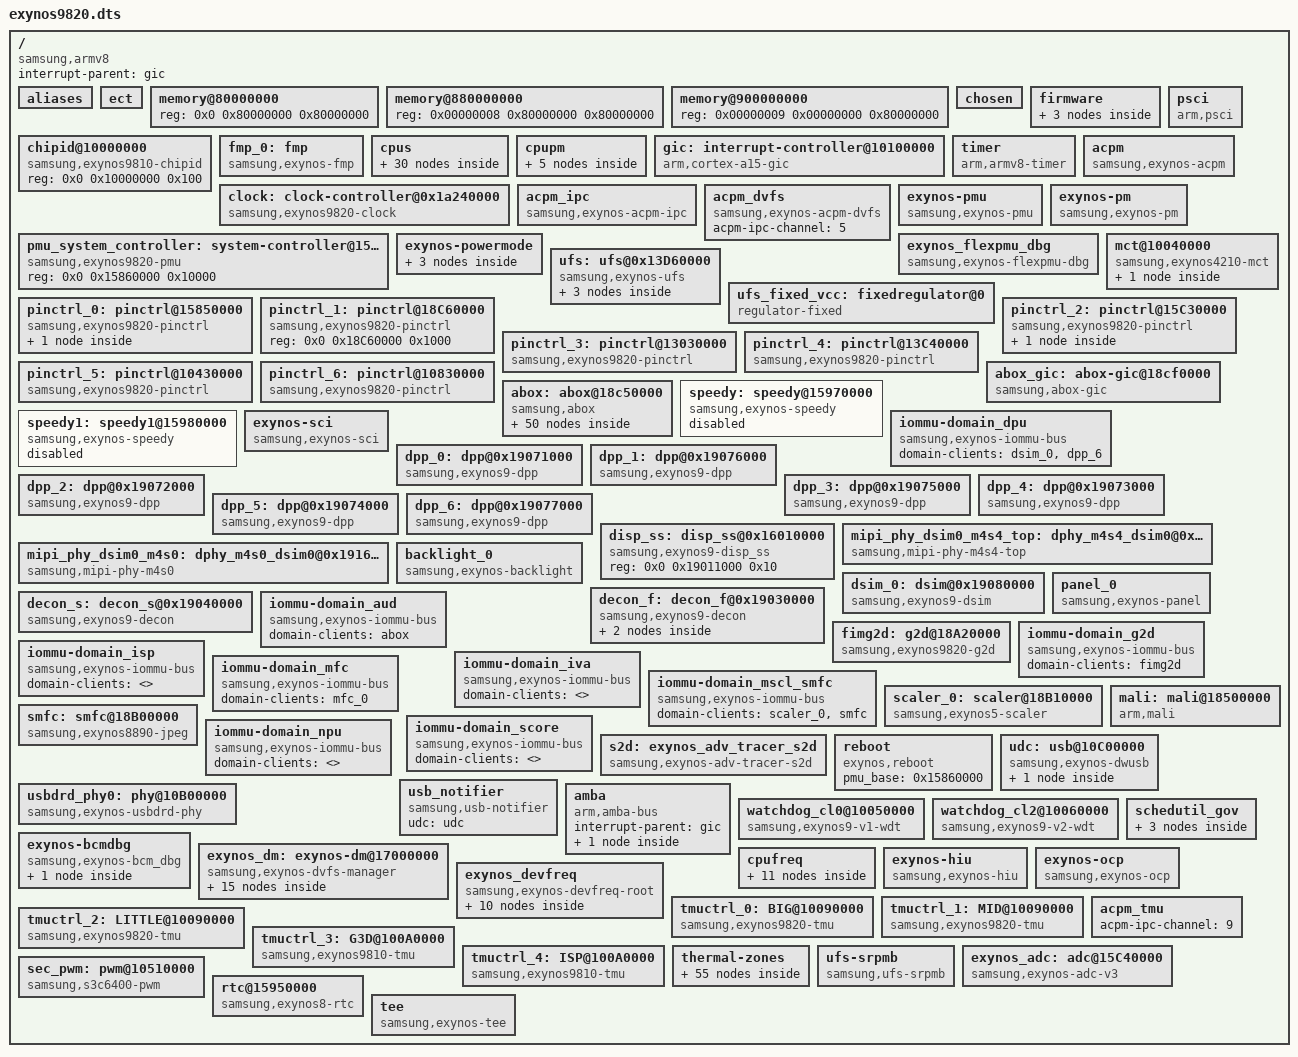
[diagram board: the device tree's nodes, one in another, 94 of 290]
/*
 * SAMSUNG EXYNOS9820 SoC device tree source
 *
 * Copyright (c) 2018 Samsung Electronics Co., Ltd.
 *		http://www.samsung.com
 *
 * SAMSUNG EXYNOS9820 SoC device nodes are listed in this file.
 * EXYNOS based board files can include this file and provide
 * values for board specfic bindings.
 *
 * This program is free software; you can redistribute it and/or modify
 * it under the terms of the GNU General Public License version 2 as
 * published by the Free Software Foundation.
 */

/dts-v1/;
#include <dt-bindings/interrupt-controller/arm-gic.h>
#include <dt-bindings/interrupt-controller/exynos9820.h>
#include <dt-bindings/soc/samsung/exynos-bcm_dbg.h>
#include "exynos9820-pm-domains.dtsi"
#include <dt-bindings/display/exynos-display.h>
#include "exynos9820-pinctrl.dtsi"
#include "exynos9820-rmem.dtsi"
#include <dt-bindings/clock/exynos9820.h>
#include "exynos9820-pmucal-dbg.dtsi"
#include "exynos9820-usi.dtsi"
#include "exynos9820-debug.dtsi"
#include <dt-bindings/ufs/ufs.h>
#include "exynos9820-sysmmu.dtsi"
#include <dt-bindings/soc/samsung/exynos9820-dm.h>
#include <dt-bindings/soc/samsung/exynos9820-devfreq.h>
#include <dt-bindings/thermal/thermal.h>
#include "exynos9820-mfc.dtsi"
#include "exynos9820-display-lcd.dtsi"

/ {
	compatible = "samsung,armv8", "samsung,exynos9820";
	interrupt-parent = <&gic>;
	#address-cells = <2>;
	#size-cells = <1>;

	aliases {
		pinctrl0 = &pinctrl_0;
		pinctrl1 = &pinctrl_1;
		pinctrl2 = &pinctrl_2;
		pinctrl3 = &pinctrl_3;
		pinctrl4 = &pinctrl_4;
		pinctrl5 = &pinctrl_5;
		pinctrl6 = &pinctrl_6;

		panel0 = &panel_0;
		dpp0 = &dpp_0;
		dpp1 = &dpp_1;
		dpp2 = &dpp_2;
		dpp3 = &dpp_3;
		dpp4 = &dpp_4;
		dpp5 = &dpp_5;
		dpp6 = &dpp_6;
		dsim0 = &dsim_0;
		bl0 = &backlight_0;
		fmp0 = &fmp_0;
		decon0 = &decon_f;
		decon1 = &decon_s;
		scaler0 = &scaler_0;
		mfc0 = &mfc_0;
	};

	ect {
		parameter_address = <0x90000000>;
		parameter_size = <0x3A000>;
	};

	memory@80000000 {
		device_type = "memory";
		reg = <0x0 0x80000000 0x80000000>;
	};

	memory@880000000 {
		device_type = "memory";
		reg = <0x00000008 0x80000000 0x80000000>;
	};

	memory@900000000 {
		device_type = "memory";
		reg = <0x00000009 0x00000000 0x80000000>;
	};

	chosen: chosen {
//		bootargs = "earlycon=exynos4210,0x10440000 console=ttySAC0,115200n8 root=/dev/ram0 rw ramdisk=8192 initrd=0x84000000,8M init=/linuxrc mem=512M clk_ignore_unused";
//		bootargs = "earlycon=exynos4210,0x10440000 console=ttySAC0,115200n8 skip_initramfs rootwait ro init=/init androidboot.dtbo_idx=0 bcm_setup=0xffffff80f8e00000 pmic_info=0x3 ccic_info=0x1 firmware_class.path=/vendor/firmware reserve-fimc=0xffffff80f9fe0000 sec_debug.cp=0 nohugeiomap epx_activate=true";
		bootargs = "console=ram skip_initramfs rootwait ro init=/init androidboot.dtbo_idx=0 bcm_setup=0xffffff80f8e00000 pmic_info=0x3 ccic_info=0x1 firmware_class.path=/vendor/firmware reserve-fimc=0xffffff80f9fe0000 sec_debug.cp=0 nohugeiomap epx_activate=true";
		linux,initrd-start = <0x84000000>;
		linux,initrd-end = <0x841FFFFF>;
	};

	firmware {
		android: android {
			compatible = "android,firmware";
			fstab {
				compatible = "android,fstab";
				vendor: vendor {
					compatible = "android,vendor";
					dev = "/dev/block/platform/13d60000.ufs/by-name/vendor";
					type = "ext4";
					mnt_flags = "ro";
					fsmgr_flags = "wait";
					status = "okay";
				};
			};
		};
	};

	chipid@10000000 {
		compatible = "samsung,exynos9810-chipid";
		reg = <0x0 0x10000000 0x100>;
	};

	fmp_0: fmp {
		compatible = "samsung,exynos-fmp";
	};

	cpus {
		#address-cells = <2>;
		#size-cells = <0>;

		cpu-map {
			cluster0 {
				coregroup0 {
					core0 {
						cpu = <&cpu0>;
					};
					core1 {
						cpu = <&cpu1>;
					};
					core2 {
						cpu = <&cpu2>;
					};
					core3 {
						cpu = <&cpu3>;
					};
				};
				coregroup1 {
					core0 {
						cpu = <&cpu4>;
					};
					core1 {
						cpu = <&cpu5>;
					};
				};
			};

			cluster1 {
				coregroup0 {
					core0 {
						cpu = <&cpu6>;
					};
					core1 {
						cpu = <&cpu7>;
					};
				};
			};

		};

		cpu0: cpu@0000 {
			device_type = "cpu";
			compatible = "arm,ananke", "arm,armv8";
			reg = <0x0 0x0000>;
			enable-method = "psci";
			cpu-idle-states = <&ANANKE_CPU_SLEEP>;
			sched-energy-data = <&ANANKE_ENERGY>;
		};

		cpu1: cpu@0001 {
			device_type = "cpu";
			compatible = "arm,ananke", "arm,armv8";
			reg = <0x0 0x0001>;
			enable-method = "psci";
			cpu-idle-states = <&ANANKE_CPU_SLEEP>;
			sched-energy-data = <&ANANKE_ENERGY>;
		};
		cpu2: cpu@0002 {
			device_type = "cpu";
			compatible = "arm,ananke", "arm,armv8";
			reg = <0x0 0x0002>;
			enable-method = "psci";
			cpu-idle-states = <&ANANKE_CPU_SLEEP>;
			sched-energy-data = <&ANANKE_ENERGY>;
		};
		cpu3: cpu@0003 {
			device_type = "cpu";
			compatible = "arm,ananke", "arm,armv8";
			reg = <0x0 0x0003>;
			enable-method = "psci";
			cpu-idle-states = <&ANANKE_CPU_SLEEP>;
			sched-energy-data = <&ANANKE_ENERGY>;
		};
		cpu4: cpu@0004 {
			device_type = "cpu";
			compatible = "arm,prometheus", "arm,armv8";
			reg = <0x0 0x0004>;
			enable-method = "psci";
			cpu-idle-states = <&PROMETHEUS_CPU_SLEEP>;
			sched-energy-data = <&PROMETHEUS_ENERGY>;
		};
		cpu5: cpu@0005 {
			device_type = "cpu";
			compatible = "arm,prometheus", "arm,armv8";
			reg = <0x0 0x0005>;
			enable-method = "psci";
			cpu-idle-states = <&PROMETHEUS_CPU_SLEEP>;
			sched-energy-data = <&PROMETHEUS_ENERGY>;
		};

		cpu6: cpu@0100 {
			device_type = "cpu";
			compatible = "arm,cheetah", "arm,armv8";
			reg = <0x0 0x0100>;
			enable-method = "psci";
			cpu-idle-states = <&CHEETAH_CPU_SLEEP>;
			sched-energy-data = <&CHEETAH_ENERGY>;
		};
		cpu7: cpu@0101 {
			device_type = "cpu";
			compatible = "arm,cheetah", "arm,armv8";
			reg = <0x0 0x0101>;
			enable-method = "psci";
			cpu-idle-states = <&CHEETAH_CPU_SLEEP>;
			sched-energy-data = <&CHEETAH_ENERGY>;
		};

		idle-states {
			entry-method = "arm,psci";

			ANANKE_CPU_SLEEP: ananke-cpu-sleep {
				idle-state-name = "c2";
				compatible = "exynos,idle-state";
				arm,psci-suspend-param = <0x0010000>;
				entry-latency-us = <70>;
				exit-latency-us = <160>;
				min-residency-us = <2000>;
				status = "okay";
			};

			PROMETHEUS_CPU_SLEEP: prometheus-cpu-sleep {
				idle-state-name = "c2";
				compatible = "exynos,idle-state";
				arm,psci-suspend-param = <0x0010000>;
				entry-latency-us = <150>;
				exit-latency-us = <190>;
				min-residency-us = <2500>;
				status = "okay";
			};

			CHEETAH_CPU_SLEEP: cheetah-cpu-sleep {
				idle-state-name = "c2";
				compatible = "exynos,idle-state";
				arm,psci-suspend-param = <0x0010000>;
				entry-latency-us = <235>;
				exit-latency-us = <220>;
				min-residency-us = <3500>;
				status = "okay";
			};
		};

		energy-data {
			ANANKE_ENERGY: ananke-energy {
				capacity-mips = <272>;
				power-coefficient = <160>;
				capacity-mips-s = <215>;
				power-coefficient-s = <130>;
			};
			PROMETHEUS_ENERGY: prometheus-energy {
				capacity-mips = <531>;
				power-coefficient = <320>;
				capacity-mips-s = <346>;
				power-coefficient-s = <259>;
			};
			CHEETAH_ENERGY: cheetah-energy {
				capacity-mips = <785>;
				power-coefficient = <760>;
				capacity-mips-s = <365>;
				power-coefficient-s = <506>;
			};
		};
	};

	psci {
		compatible = "arm,psci";
		method = "smc";
		cpu_suspend = <0xC4000001>;
		cpu_off = <0x84000002>;
		cpu_on = <0xC4000003>;
	};

	cpupm {
		#define POWERMODE_TYPE_CLUSTER	0
		#define POWERMODE_TYPE_SYSTEM	1

		cpd_cl0 {
			device_type = "cpupm";
			target-residency = <10000>;
			psci-index = <128>;
			type = <POWERMODE_TYPE_CLUSTER>;
			siblings = "0-5";
		};

		cpd_cl1 {
			device_type = "cpupm";
			target-residency = <10000>;
			psci-index = <128>;
			type = <POWERMODE_TYPE_CLUSTER>;
			siblings = "6-7";
			entry-allowed = "6-7";
		};

		vcpu_topology {
			vcluster_cnt = <3>;
			vcluster0_sibling = "0-3";
			vcluster1_sibling = "4-5";
			vcluster2_sibling = "6-7";
		};

		sicd {
			device_type = "cpupm";
			target-residency = <10000>;
			psci-index = <256>;
			type = <POWERMODE_TYPE_SYSTEM>;
			siblings = "0-7";
			entry-allowed = "0-5";
			system-idle;
		};

		idle-ip {
			idle-ip-list =
				"10510000.pwm",		/* [ 0] pwm      */
				"15c40000.adc",		/* [ 1] adc      */
				"10860000.hsi2c",	/* [ 2] hsi2c_0  */
				"10870000.hsi2c",	/* [ 3] hsi2c_1  */
				"10880000.hsi2c",	/* [ 4] hsi2c_2  */
				"10890000.hsi2c",	/* [ 5] hsi2c_3  */
				"10450000.hsi2c",	/* [ 6] hsi2c_4  */
				"10460000.hsi2c",	/* [ 7] hsi2c_5  */
				"10470000.hsi2c",	/* [ 8] hsi2c_6  */
				"10480000.hsi2c",	/* [ 9] hsi2c_7  */
				"10490000.hsi2c",	/* [10] hsi2c_8  */
				"104a0000.hsi2c",	/* [11] hsi2c_9  */
				"104b0000.hsi2c",	/* [12] hsi2c_10 */
				"104c0000.hsi2c",	/* [13] hsi2c_11 */
				"104d0000.hsi2c",	/* [14] hsi2c_12 */
				"104e0000.hsi2c",	/* [15] hsi2c_13 */
				"104f0000.hsi2c",	/* [16] hsi2c_14 */
				"10500000.hsi2c",	/* [17] hsi2c_15 */
				"108a0000.hsi2c",	/* [18] hsi2c_16 */
				"108b0000.hsi2c",	/* [19] hsi2c_17 */
				"108c0000.hsi2c",	/* [20] hsi2c_18 */
				"108d0000.hsi2c",	/* [21] hsi2c_19 */
				"108e0000.hsi2c",	/* [22] hsi2c_20 */
				"108f0000.hsi2c",	/* [23] hsi2c_21 */
				"10910000.hsi2c",	/* [25] hsi2c_23 */
				"10920000.hsi2c",	/* [26] hsi2c_24 */
				"10930000.hsi2c",	/* [27] hsi2c_25 */
				"10940000.hsi2c",	/* [28] hsi2c_26 */
				"10950000.hsi2c",	/* [29] hsi2c_27 */
				"10520000.hsi2c",	/* [30] hsi2c_28 */
				"10530000.hsi2c",	/* [31] hsi2c_29 */
				"10540000.hsi2c",	/* [32] hsi2c_30 */
				"10550000.hsi2c",	/* [33] hsi2c_31 */
				"10560000.hsi2c",	/* [34] hsi2c_32 */
				"10570000.hsi2c",	/* [35] hsi2c_33 */
				"10580000.hsi2c",	/* [36] hsi2c_34 */
				"10590000.hsi2c",	/* [37] hsi2c_35 */
				"10970000.hsi2c",	/* [38] hsi2c_36 */
				"10990000.hsi2c",	/* [39] hsi2c_37 */
				"109a0000.hsi2c",	/* [40] hsi2c_38 */
				"15d00000.hsi2c",	/* [41] hsi2c_39 */
				"15d10000.hsi2c",	/* [42] hsi2c_40 */
				"15d20000.hsi2c",	/* [43] hsi2c_41 */
				"15d30000.hsi2c",	/* [44] hsi2c_42 */
				"15d40000.hsi2c",	/* [45] hsi2c_43 */
				"15d50000.hsi2c",	/* [46] hsi2c_44 */
				"15d60000.hsi2c",	/* [47] hsi2c_45 */
				"15d70000.hsi2c",	/* [48] hsi2c_46 */
				"10850000.spi",		/* [49] spi_0    */
				"10450000.spi",		/* [50] spi_1    */
				"10470000.spi",		/* [51] spi_2    */
				"10490000.spi",		/* [52] spi_3    */
				"104b0000.spi",		/* [53] spi_4    */
				"104d0000.spi",		/* [54] spi_5    */
				"104f0000.spi",		/* [55] spi_6    */
				"108a0000.spi",		/* [56] spi_7    */
				"108c0000.spi",		/* [57] spi_8    */
				"108e0000.spi",		/* [58] spi_9    */
				"10900000.spi",		/* [59] spi_10   */
				"10920000.spi",		/* [60] spi_11   */
				"10940000.spi",		/* [61] spi_12   */
				"10520000.spi",		/* [62] spi_13   */
				"10540000.spi",		/* [63] spi_14   */
				"10560000.spi",		/* [64] spi_15   */
				"10580000.spi",		/* [65] spi_16   */
				"10970000.spi",		/* [66] spi_17   */
				"10990000.spi",		/* [67] spi_18   */
				"15d00000.spi",		/* [68] spi_19   */
				"15d20000.spi",		/* [69] spi_20   */
				"15d40000.spi",		/* [70] spi_21   */
				"15d60000.spi",		/* [71] spi_22   */
				"13d60000.ufs",		/* [72] ufs 	 */
				"10c00000.usb",		/* [73] usb 	 */
				"pd-aud",		/* [74] pd-aud	 */
				"pd-dcf",		/* [75] pd-dcf   */
				"pd-dcpost",		/* [76] pd-dcpost*/
				"pd-dcrd",		/* [77] pd-dcrd  */
				"pd-dpu",		/* [78] pd-dpu   */
				"pd-dspm",		/* [79] pd-dspm  */
				"pd-dsps",		/* [80] pd-dsps  */
				"pd-g2d",		/* [81] pd-g2d   */
				"pd-embedded_g3d",	/* [82] pd-embedded_g3d */
				"pd-isppre",		/* [83] pd-isppre*/
				"pd-isphq",		/* [84] pd-isphq */
				"pd-isplp",		/* [85] pd-isplp */
				"pd-iva",		/* [86] pd-iva   */
				"pd-mfc",		/* [87] pd-mfc   */
				"pd-vts",		/* [88] pd-vts   */
				"13ed0000.pcie0",	/* [89] pcie0    */
				"13120000.pcie1",	/* [90] pcie1    */
				"pd-vra2",		/* [91] vra2	 */
				"pd-npu0",		/* [92] npu0	 */
				"pd-npu1",		/* [93] npu1	 */
				"pd-fsys0a",		/* [94] fsys0a	 */
				"13d00000.dwmmc2",	/* [95] dwmmc2	 */
				"130b0000.displayport",	/* [96] displayport */
				"19080000.dsim";	/* [97] pd-dpu   */
				/* Append idle ip with ascending number from here
				 * Be advised that the end of entry must be with semicolon, not comma.
				 * and should be set in idle-ip-mask entry
				 */

				/* to here idle ip */

			fix-idle-ip =
				"acpm_dvfs",
				"dbg_core";
			fix-idle-ip-index =
				<110>,
				<111>;

			idle-ip-mask =
				<0>,  <1>,  <2>,  <3>,  <4>,  <5>,  <6>,  <7>,  <8>,  <9>,
				<10>, <11>, <12>, <13>, <14>, <15>, <16>, <17>, <18>, <19>,
				<20>, <21>, <22>, <23>, <24>, <25>, <26>, <27>, <28>, <29>,
				<30>, <31>, <32>, <33>, <34>, <35>, <36>, <37>, <38>, <39>,
				<40>, <41>, <42>, <43>, <44>, <45>, <46>, <47>, <48>, <49>,
				<50>, <51>, <52>, <53>, <54>, <55>, <56>, <57>, <58>, <59>,
				<60>, <61>, <62>, <63>, <64>, <65>, <66>, <67>, <68>, <69>,
				<70>, <71>, <72>, <73>,       <75>, <76>, <77>,       <79>,
				<80>, <81>, <82>, <83>, <84>, <85>, <86>, <87>,       <89>,
				<90>, <91>, <92>, <93>,       <95>, <96>, <97>,
				/* fix-idle-ip */
				<111>;
		};
	};

	gic:interrupt-controller@10100000 {
		compatible = "arm,cortex-a15-gic", "arm,cortex-a9-gic";
		#interrupt-cells = <3>;
		#address-cells = <0>;
		interrupt-controller;
		reg =	<0x0 0x10101000 0x1000>,
			<0x0 0x10102000 0x1000>,
			<0x0 0x10104000 0x2000>,
			<0x0 0x10106000 0x2000>;
		interrupts = <1 9 0xf04>;
	};

	timer {
	        compatible = "arm,armv8-timer";
		interrupts = <GIC_PPI 13
				(GIC_CPU_MASK_SIMPLE(8) | IRQ_TYPE_LEVEL_LOW)>,
			     <GIC_PPI 14
				(GIC_CPU_MASK_SIMPLE(8) | IRQ_TYPE_LEVEL_LOW)>,
			     <GIC_PPI 11
				(GIC_CPU_MASK_SIMPLE(8) | IRQ_TYPE_LEVEL_LOW)>,
			     <GIC_PPI 10
				(GIC_CPU_MASK_SIMPLE(8) | IRQ_TYPE_LEVEL_LOW)>;
	        clock-frequency = <26000000>;
		use-clocksource-only;
		use-physical-timer;
	};

	clock: clock-controller@0x1a240000 {
		compatible = "samsung,exynos9820-clock";
		reg = <0x0 0x1a240000 0x8000>;
		#clock-cells = <1>;
		acpm-ipc-channel = <0>;
	};

	acpm {
		compatible = "samsung,exynos-acpm";
		#address-cells = <2>;
		#size-cells = <1>;
		acpm-ipc-channel = <4>;
		fvmap_offset = <0xA400>;
		reg = <0x0 0x15830000 0x1000>;		/* TIMER_APM */
		reg-names = "timer_apm";
		peritimer-cnt = <0xFFFF>;
	};

	acpm_ipc {
		compatible = "samsung,exynos-acpm-ipc";
		#address-cells = <2>;
		#size-cells = <1>;
		interrupts = <GIC_SPI INTREQ__MAILBOX_APM2AP IRQ_TYPE_LEVEL_HIGH>;	/* AP2APM MAILBOX SPI NUM*/
		reg = <0x0 0x15900000 0x1000>,		/* AP2APM MAILBOX */
			<0x0 0x2039000 0x30000>;	/* APM SRAM */
		initdata-base = <0x7000>;
		num-timestamps = <32>;
		debug-log-level = <0>;
		logging-period = <500>;
		dump-base = <0x203C000>;
		dump-size = <0x2D000>;			/* 180KB */
	};

	acpm_dvfs {
		compatible = "samsung,exynos-acpm-dvfs";
		acpm-ipc-channel = <5>;
	};

	exynos-pmu {
		compatible = "samsung,exynos-pmu";
		samsung,syscon-phandle = <&pmu_system_controller>;
		reg = <0x0 0x15860000 0x10000>;
		reg-names = "pmu_alive";
	};

	pmu_system_controller: system-controller@15860000 {
		compatible = "samsung,exynos9820-pmu", "syscon";
		reg = <0x0 0x15860000 0x10000>;
	};

	exynos-pm {
		compatible = "samsung,exynos-pm";
		reg = <0x0 0x15850000 0x1000>,
		    <0x0 0x10101200 0x100>;
		reg-names = "gpio_alive_base",
			"gicd_ispendrn_base";
		num-eint = <34>;
		num-gic = <16>;
		suspend_mode_idx = <8>;		/* SYS_SLEEP */
		suspend_psci_idx = <1024>;	/* PSCI_SYSTEM_SLEEP */
		cp_call_mode_idx = <10>;	/* SYS_SLEEP_AUD_ON */
		cp_call_psci_idx = <1024>;	/* PSCI_SYSTEM_SLEEP */

		usbl2_suspend_available = <1>;	/* SYS_SLEEP_USBL2 */
		usbl2_suspend_mode_idx = <12>;	/* PSCI_SYSTEM_SLEEP */

			   /* WAKEUP_STAT,	WAKEUP2_STAT*/
		wakeup_stat = <0x3950>,		<0x3954>;
	};

	exynos-powermode {
		wakeup-masks {
			/*
			 * wakeup_mask configuration
			 *	        SICD		SICD_CPD	AFTR		STOP
			 *              LPD		LPA		ALPA		DSTOP
			 *              SLEEP		SLEEP_VTS_ON	SLEEP_AUD_ON	FAPO
			 *		USB_L2
			 */
			wakeup-mask {
				mask = <0x7ff81fff>,	<0x0>,		<0x0>,		<0x0>,
				       <0x0>,		<0x0>,		<0x0>,		<0x0>,
				       <0x1f6f>,	<0x1f6f>,	<0x1f6f>,	<0x0>,
				       <0x81f6f>;
				mask-offset = <0x3944>;
				stat-offset = <0x3950>;
			};
			wakeup-mask2 {
				mask = <0xf>,		<0x0>,		<0x0>,		<0x0>,
				       <0x0>,		<0x0>,		<0x0>,		<0x0>,
				       <0xf>,		<0xf>,		<0xf>,		<0x0>,
				       <0xc>;
				mask-offset = <0x3964>;
				stat-offset = <0x3954>;
			};
		};
	};

	exynos_flexpmu_dbg {
		compatible = "samsung,exynos-flexpmu-dbg";
		#address-cells = <2>;
		#size-cells = <1>;
		data-base = <0x204bc00>;
		data-size = <0x400>;
	};

	mct@10040000 {
		compatible = "samsung,exynos4210-mct";
		reg = <0x0 0x10040000 0x800>;
		interrupt-controller;
		#interrupt-cells = <1>;
		interrupt-parent = <&mct_map>;
		interrupts =	<0>, <1>, <2>, <3>,
				<4>, <5>, <6>, <7>,
				<8>, <9>, <10>, <11>;
		clocks = <&clock 1>, <&clock 15>;
		clock-names = "fin_pll", "mct";
		use-clockevent-only;

		mct_map: mct-map {
			#interrupt-cells = <1>;
			#address-cells = <0>;
			#size-cells = <0>;
			interrupt-map = <0 &gic 0 INTREQ__MCT_G0 IRQ_TYPE_LEVEL_HIGH>,
					<1 &gic 0 INTREQ__MCT_G1 IRQ_TYPE_LEVEL_HIGH>,
					<2 &gic 0 INTREQ__MCT_G2 IRQ_TYPE_LEVEL_HIGH>,
					<3 &gic 0 INTREQ__MCT_G3 IRQ_TYPE_LEVEL_HIGH>,
					<4 &gic 0 INTREQ__MCT_L0 IRQ_TYPE_LEVEL_HIGH>,
					<5 &gic 0 INTREQ__MCT_L1 IRQ_TYPE_LEVEL_HIGH>,
					<6 &gic 0 INTREQ__MCT_L2 IRQ_TYPE_LEVEL_HIGH>,
					<7 &gic 0 INTREQ__MCT_L3 IRQ_TYPE_LEVEL_HIGH>,
					<8 &gic 0 INTREQ__MCT_L4 IRQ_TYPE_LEVEL_HIGH>,
					<9 &gic 0 INTREQ__MCT_L5 IRQ_TYPE_LEVEL_HIGH>,
					<10 &gic 0 INTREQ__MCT_L6 IRQ_TYPE_LEVEL_HIGH>,
					<11 &gic 0 INTREQ__MCT_L7 IRQ_TYPE_LEVEL_HIGH>;
		};
	};

	ufs: ufs@0x13D60000 {
		/* ----------------------- */
		/* 1. SYSTEM CONFIGURATION */
		/* ----------------------- */
		compatible ="samsung,exynos-ufs";
		#address-cells = <2>;
		#size-cells = <1>;
		ranges;

		reg =
			<0x0 0x13D60000 0x200>,	/* 0: HCI standard */
			<0x0 0x13D61100 0x200>,	/* 1: Vendor specificed */
			<0x0 0x13D50000 0x8000>,	/* 2: UNIPRO */
			<0x0 0x13D70000 0x100>;	/* 3: UFS protector */
		interrupts = <GIC_SPI INTREQ__UFS_EMBD IRQ_TYPE_LEVEL_HIGH>;
		pinctrl-names = "default";
		pinctrl-0 = <&ufs_rst_n &ufs_refclk_out>;
		clocks =
			/* aclk clock */
			<&clock GATE_UFS_EMBD>,
			/* unipro clocks */
			<&clock UFS_EMBD>;

		clock-names =
			/* aclk clocks */
			"GATE_UFS_EMBD",
			/* unipro clocks */
			"UFS_EMBD";

		/* PM QoS for INT power domain */
		ufs-pm-qos-int = <400000>;

		/* PM QoS for FSYS0 power domain */


		/* DMA coherent callback, should be coupled with 'ufs-sys' */
		dma-coherent;

		/* ----------------------- */
		/* 2. UFS COMMON           */
		/* ----------------------- */
		freq-table-hz = <0 0>, <0 0>;

		vcc-supply = <&ufs_fixed_vcc>;
		vcc-fixed-regulator;


		/* ----------------------- */
		/* 3. UFS EXYNOS           */
		/* ----------------------- */
		hw-rev = <UFS_VER_0006>;

		/* power mode change */
		ufs,pmd-attr-lane = /bits/ 8 <2>;
		ufs,pmd-attr-gear = /bits/ 8 <3>;

		/* hiberantion */
		ufs-rx-min-activate-time-cap = <3>;
		ufs-rx-hibern8-time-cap = <2>;
		ufs-tx-hibern8-time-cap = <2>;

                /* evt version 1.x for UFS CAL */
		evt-ver = /bits/ 8 <1>;

		/* board type for UFS CAL */
		brd-for-cal = /bits/ 8 <1>;  /* (1:SMDK, 16:UNIV) board */
		fmp-id = <0>;
		smu-id = <0>;

		/* ----------------------- */
		/* 4. ADDITIONAL NODES     */
		/* ----------------------- */
		/* PHY isolation */
		ufs-phy {
			#address-cells = <2>;
			#size-cells = <1>;
			ranges;
			reg = <0x0 0x13D64000 0x800>;

		};

		/* SYSREG */
		ufs-io-coherency {
			#address-cells = <2>;
			#size-cells = <1>;
			ranges;

			reg =
				<0x0 0x13C10700 0x4>;

			mask = <(BIT_22 | BIT_23)>;
			bits = <(BIT_22 | BIT_23)>;
		};

		ufs-cport {
			reg =
			<0x0 0x13D68000 0x804>;
		};
	};

	ufs_fixed_vcc: fixedregulator@0 {
		       compatible = "regulator-fixed";
		       regulator-name = "ufs-vcc";
		       gpio = <&gpd0 2 0>;
		       regulator-boot-on;
		       enable-active-high;
	};

	/* ALIVE */
	pinctrl_0: pinctrl@15850000 {
		compatible = "samsung,exynos9820-pinctrl";
		reg = <0x0 0x15850000 0x1000>;
		interrupts = <GIC_SPI INTREQ__ALIVE_EINT0 IRQ_TYPE_LEVEL_HIGH>, <GIC_SPI INTREQ__ALIVE_EINT1 IRQ_TYPE_LEVEL_HIGH>, <GIC_SPI INTREQ__ALIVE_EINT2 IRQ_TYPE_LEVEL_HIGH>,
			     <GIC_SPI INTREQ__ALIVE_EINT3 IRQ_TYPE_LEVEL_HIGH>, <GIC_SPI INTREQ__ALIVE_EINT4 IRQ_TYPE_LEVEL_HIGH>, <GIC_SPI INTREQ__ALIVE_EINT5 IRQ_TYPE_LEVEL_HIGH>,
			     <GIC_SPI INTREQ__ALIVE_EINT6 IRQ_TYPE_LEVEL_HIGH>, <GIC_SPI INTREQ__ALIVE_EINT7 IRQ_TYPE_LEVEL_HIGH>, <GIC_SPI INTREQ__ALIVE_EINT8 IRQ_TYPE_LEVEL_HIGH>,
			     <GIC_SPI INTREQ__ALIVE_EINT9 IRQ_TYPE_LEVEL_HIGH>, <GIC_SPI INTREQ__ALIVE_EINT10 IRQ_TYPE_LEVEL_HIGH>, <GIC_SPI INTREQ__ALIVE_EINT11 IRQ_TYPE_LEVEL_HIGH>,
			     <GIC_SPI INTREQ__ALIVE_EINT12 IRQ_TYPE_LEVEL_HIGH>, <GIC_SPI INTREQ__ALIVE_EINT13 IRQ_TYPE_LEVEL_HIGH>, <GIC_SPI INTREQ__ALIVE_EINT14 IRQ_TYPE_LEVEL_HIGH>,
			     <GIC_SPI INTREQ__ALIVE_EINT15 IRQ_TYPE_LEVEL_HIGH>, <GIC_SPI INTREQ__ALIVE_EINT16 IRQ_TYPE_LEVEL_HIGH>, <GIC_SPI INTREQ__ALIVE_EINT17 IRQ_TYPE_LEVEL_HIGH>,
			     <GIC_SPI INTREQ__ALIVE_EINT18 IRQ_TYPE_LEVEL_HIGH>, <GIC_SPI INTREQ__ALIVE_EINT19 IRQ_TYPE_LEVEL_HIGH>, <GIC_SPI INTREQ__ALIVE_EINT20 IRQ_TYPE_LEVEL_HIGH>,
			     <GIC_SPI INTREQ__ALIVE_EINT21 IRQ_TYPE_LEVEL_HIGH>, <GIC_SPI INTREQ__ALIVE_EINT22 IRQ_TYPE_LEVEL_HIGH>, <GIC_SPI INTREQ__ALIVE_EINT23 IRQ_TYPE_LEVEL_HIGH>,
			     <GIC_SPI INTREQ__ALIVE_EINT24 IRQ_TYPE_LEVEL_HIGH>, <GIC_SPI INTREQ__ALIVE_EINT25 IRQ_TYPE_LEVEL_HIGH>, <GIC_SPI INTREQ__ALIVE_EINT26 IRQ_TYPE_LEVEL_HIGH>,
			     <GIC_SPI INTREQ__ALIVE_EINT27 IRQ_TYPE_LEVEL_HIGH>, <GIC_SPI INTREQ__ALIVE_EINT28 IRQ_TYPE_LEVEL_HIGH>, <GIC_SPI INTREQ__ALIVE_EINT29 IRQ_TYPE_LEVEL_HIGH>,
			     <GIC_SPI INTREQ__ALIVE_EINT30 IRQ_TYPE_LEVEL_HIGH>, <GIC_SPI INTREQ__ALIVE_EINT31 IRQ_TYPE_LEVEL_HIGH>, <GIC_SPI INTREQ__ALIVE_EINT32 IRQ_TYPE_LEVEL_HIGH>,
			     <GIC_SPI INTREQ__ALIVE_EINT33 IRQ_TYPE_LEVEL_HIGH>;

		wakeup-interrupt-controller {
			compatible = "samsung,exynos7-wakeup-eint";
		};
	};

	/* AUD */
	pinctrl_1: pinctrl@18C60000{
		compatible = "samsung,exynos9820-pinctrl";
		reg = <0x0 0x18C60000 0x1000>;
	};

	/* CMGP */
	pinctrl_2: pinctrl@15C30000{
		compatible = "samsung,exynos9820-pinctrl";
		reg = <0x0 0x15C30000 0x1000>;
		interrupts = <GIC_SPI INTREQ__EXT_INTM0_0 IRQ_TYPE_LEVEL_HIGH>, <GIC_SPI INTREQ__EXT_INTM0_1 IRQ_TYPE_LEVEL_HIGH>,
			     <GIC_SPI INTREQ__EXT_INTM0_2 IRQ_TYPE_LEVEL_HIGH>, <GIC_SPI INTREQ__EXT_INTM0_3 IRQ_TYPE_LEVEL_HIGH>,
			     <GIC_SPI INTREQ__EXT_INTM0_4 IRQ_TYPE_LEVEL_HIGH>, <GIC_SPI INTREQ__EXT_INTM0_5 IRQ_TYPE_LEVEL_HIGH>,
			     <GIC_SPI INTREQ__EXT_INTM0_6 IRQ_TYPE_LEVEL_HIGH>, <GIC_SPI INTREQ__EXT_INTM0_7 IRQ_TYPE_LEVEL_HIGH>,
			     <GIC_SPI INTREQ__EXT_INTM1_0 IRQ_TYPE_LEVEL_HIGH>, <GIC_SPI INTREQ__EXT_INTM1_1 IRQ_TYPE_LEVEL_HIGH>,
			     <GIC_SPI INTREQ__EXT_INTM1_2 IRQ_TYPE_LEVEL_HIGH>, <GIC_SPI INTREQ__EXT_INTM1_3 IRQ_TYPE_LEVEL_HIGH>,
			     <GIC_SPI INTREQ__EXT_INTM1_4 IRQ_TYPE_LEVEL_HIGH>, <GIC_SPI INTREQ__EXT_INTM1_5 IRQ_TYPE_LEVEL_HIGH>,
			     <GIC_SPI INTREQ__EXT_INTM1_6 IRQ_TYPE_LEVEL_HIGH>, <GIC_SPI INTREQ__EXT_INTM1_7 IRQ_TYPE_LEVEL_HIGH>,
			     <GIC_SPI INTREQ__EXT_INTM1_8 IRQ_TYPE_LEVEL_HIGH>, <GIC_SPI INTREQ__EXT_INTM1_9 IRQ_TYPE_LEVEL_HIGH>,
			     <GIC_SPI INTREQ__EXT_INTM2_0 IRQ_TYPE_LEVEL_HIGH>, <GIC_SPI INTREQ__EXT_INTM2_1 IRQ_TYPE_LEVEL_HIGH>,
			     <GIC_SPI INTREQ__EXT_INTM2_2 IRQ_TYPE_LEVEL_HIGH>, <GIC_SPI INTREQ__EXT_INTM2_3 IRQ_TYPE_LEVEL_HIGH>,
			     <GIC_SPI INTREQ__EXT_INTM2_4 IRQ_TYPE_LEVEL_HIGH>, <GIC_SPI INTREQ__EXT_INTM2_5 IRQ_TYPE_LEVEL_HIGH>,
			     <GIC_SPI INTREQ__EXT_INTM2_6 IRQ_TYPE_LEVEL_HIGH>, <GIC_SPI INTREQ__EXT_INTM2_7 IRQ_TYPE_LEVEL_HIGH>,
			     <GIC_SPI INTREQ__EXT_INTM2_8 IRQ_TYPE_LEVEL_HIGH>, <GIC_SPI INTREQ__EXT_INTM2_9 IRQ_TYPE_LEVEL_HIGH>,
			     <GIC_SPI INTREQ__EXT_INTM3_0 IRQ_TYPE_LEVEL_HIGH>, <GIC_SPI INTREQ__EXT_INTM3_1 IRQ_TYPE_LEVEL_HIGH>;

		wakeup-interrupt-controller {
			compatible = "samsung,exynos7-wakeup-eint";
		};
	};

	/* FSYS0 */
	pinctrl_3: pinctrl@13030000 {
		compatible = "samsung,exynos9820-pinctrl";
		reg = <0x0 0x13030000 0x1000>;
		interrupts = <GIC_SPI INTREQ__GPIO_FSYS0 IRQ_TYPE_LEVEL_HIGH>;
	};

	/* FSYS1 */
	pinctrl_4: pinctrl@13C40000 {
		compatible = "samsung,exynos9820-pinctrl";
		reg = <0x0 0x13C40000 0x1000>;
		interrupts = <GIC_SPI INTREQ__GPIO_FSYS1 IRQ_TYPE_LEVEL_HIGH>;
	};

	/* PERIC0 */
	pinctrl_5: pinctrl@10430000 {
		compatible = "samsung,exynos9820-pinctrl";
		reg = <0x0 0x10430000 0x1000>;
		interrupts = <GIC_SPI INTREQ__GPIO_PERIC0 IRQ_TYPE_LEVEL_HIGH>;
	};

	/* PERIC1 */
	pinctrl_6: pinctrl@10830000 {
		compatible = "samsung,exynos9820-pinctrl";
		reg = <0x0 0x10830000 0x1000>;
		interrupts = <GIC_SPI INTREQ__GPIO_PERIC1 IRQ_TYPE_LEVEL_HIGH>;
	};
#if 0
	/* VTS */
	pinctrl_7: pinctrl@15580000 {
		compatible = "samsung,exynos9820-pinctrl";
		reg = <0x0 0x15580000 0x1000>;
	};
#endif

	abox_gic: abox-gic@18cf0000 {
		compatible = "samsung,abox-gic";
		reg = <0x0 0x18cf1000 0x1000>, <0x0 0x18cf2000 0x1004>;
		reg-names = "gicd", "gicc";
		interrupts = <GIC_SPI INTREQ__AUD_ABOX_GIC400 IRQ_TYPE_LEVEL_HIGH>;
	};

	abox: abox@18c50000 {
		compatible = "samsung,abox";
		reg = <0x0 0x18c50000 0x10000>, <0x0 0x18c10000 0x10000>,
			<0x0 0x18d00000 0x59000>, <0x0 0x18ce0000 0x10000>;
		reg-names = "sfr", "sysreg", "sram", "timer";
		#address-cells = <2>;
		#size-cells = <1>;
		ranges;
		iommus = <&sysmmu_aud>;
		clocks = <&clock PLL_OUT_AUD0>, <&clock PLL_OUT_AUD1>, <&clock DOUT_CLK_AUD_AUDIF>,
			<&clock DOUT_CLK_AUD_DMIC>, <&clock DOUT_CLK_AUD_BUS>, <&clock DOUT_CLK_AUD_CNT>;
		clock-names = "pll", "pll1", "audif", "dmic", "bus", "cnt";
		#sound-dai-cells = <1>;
		samsung,quirks = "try to asrc off";
		samsung,ipc-tx-offset = <0x2f000>;
		samsung,ipc-rx-offset = <0x2f300>;
		samsung,ipc-tx-ack-offset = <0x2f2fc>;
		samsung,ipc-rx-ack-offset = <0x2f5fc>;
		samsung,ipc-tx-area = <0x1 0x850000 0x4000>;
		samsung,ipc-rx-area = <0x1 0x854000 0x4000>;
		samsung,handshake-area = <0x0 0x2f2e0 0x20>;
		samsung,abox-gic = <&abox_gic>;
		samsung,uaif-max-div = <512>;
		samsung,pm-qos-int = <0 0 0 0 0>;
		samsung,pm-qos-aud = <1180000 800000 590000 394000 0>;

		abox_core0: abox-core@18c55000 {
			compatible = "samsung,abox-core";
			reg = <0x0 0x18c55000 0x80>;
			reg-names = "gpr";
			samsung,id = <0>;
			samsung,type = "CA32";
			samsung,pmu_power = <0x2d80 0x1>;
			samsung,pmu_enable = <0x2da0 0x1>;
			samsung,pmu_standby = <0x2da4 0x11>;
			abox_firmware_sram0: abox-firmware-sram0 {
				samsung,name = "calliope_sram.bin";
				samsung,area = <0>; /* 0:SRAM, 1:DRAM */
				samsung,offset = <0x0>;
			};
			abox_firmware_dram0: abox-firmware-dram0 {
				samsung,name = "calliope_dram.bin";
				samsung,area = <1>; /* 0:SRAM, 1:DRAM */
				samsung,offset = <0x0>;
			};
		};

		abox_core1: abox-core@18c55080 {
			compatible = "samsung,abox-core";
			reg = <0x0 0x18c55080 0x80>, <0x0 0x18c55100 0x4>;
			reg-names = "gpr", "status";
			samsung,id = <1>;
			samsung,type = "CA32";
			samsung,pmu_power = <0x2e00 0x1>;
			samsung,pmu_enable = <0x2e20 0x1>;
			samsung,pmu_standby = <0x2e24 0x1>;
			abox_firmware_sram1: abox-firmware-sram1 {
				samsung,name = "calliope_sram_2.bin";
				samsung,area = <0>; /* 0:SRAM, 1:DRAM */
				samsung,offset = <0x32000>;
			};
			abox_firmware_dram1: abox-firmware-dram1 {
				samsung,name = "calliope_dram_2.bin";
				samsung,area = <1>; /* 0:SRAM, 1:DRAM */
				samsung,offset = <0x280000>;
			};
		};

		abox_rdma_0: abox-rdma@18c51000 {
			compatible = "samsung,abox-rdma";
			reg = <0x0 0x18c51000 0x100>;
			reg-names = "sfr";
			samsung,id = <0>;
			samsung,type = "normal";
			samsung,buffer_type = "dma";
			#sound-dai-cells = <0>;
		};

		abox_rdma_1: abox-rdma@18c51100 {
			compatible = "samsung,abox-rdma";
			reg = <0x0 0x18c51100 0x100>;
			reg-names = "sfr";
			samsung,id = <1>;
			samsung,type = "normal";
			samsung,buffer_type = "dma";
			#sound-dai-cells = <0>;
		};

		abox_rdma_2: abox-rdma@18c51200 {
			compatible = "samsung,abox-rdma";
			reg = <0x0 0x18c51200 0x100>;
			reg-names = "sfr";
			samsung,id = <2>;
			samsung,type = "normal";
			samsung,buffer_type = "ion";
			#sound-dai-cells = <0>;
		};

		abox_rdma_3: abox-rdma@18c51300 {
			compatible = "samsung,abox-rdma";
			reg = <0x0 0x18c51300 0x100>;
			reg-names = "sfr";
			samsung,id = <3>;
			samsung,type = "sync";
			samsung,buffer_type = "dma";
			#sound-dai-cells = <0>;
		};

		abox_rdma_4: abox-rdma@18c51400 {
			compatible = "samsung,abox-rdma";
			reg = <0x0 0x18c51400 0x100>;
			reg-names = "sfr";
			samsung,id = <4>;
			samsung,type = "call";
			#sound-dai-cells = <0>;
			samsung,buffer_type = "dma";
			samsung,asrc-id = <10>;
		};

		abox_rdma_5: abox-rdma@18c51500 {
			compatible = "samsung,abox-rdma";
			reg = <0x0 0x18c51500 0x100>, <0x0 0x18d2f600 0x70>;
			reg-names = "sfr", "mailbox";
			samsung,id = <5>;
			samsung,type = "compress";
			samsung,buffer_type = "dma";
			#sound-dai-cells = <0>;
		};

		abox_rdma_6: abox-rdma@18c51600 {
			compatible = "samsung,abox-rdma";
			reg = <0x0 0x18c51600 0x100>;
			reg-names = "sfr";
			samsung,id = <6>;
			samsung,type = "realtime";
			samsung,buffer_type = "dma";
			#sound-dai-cells = <0>;
		};

		abox_rdma_7: abox-rdma@18c51700 {
			compatible = "samsung,abox-rdma";
			reg = <0x0 0x18c51700 0x100>;
			reg-names = "sfr";
			samsung,id = <7>;
			samsung,type = "realtime";
			samsung,buffer_type = "dma";
			#sound-dai-cells = <0>;
		};

		abox_rdma_8: abox-rdma@18c51800 {
			compatible = "samsung,abox-rdma";
			reg = <0x0 0x18c51800 0x100>;
			reg-names = "sfr";
			samsung,id = <8>;
			samsung,type = "normal";
			samsung,buffer_type = "dma";
			#sound-dai-cells = <0>;
		};

		abox_rdma_9: abox-rdma@18c51900 {
			compatible = "samsung,abox-rdma";
			reg = <0x0 0x18c51900 0x100>;
			reg-names = "sfr";
			samsung,id = <9>;
			samsung,type = "normal";
			samsung,buffer_type = "dma";
			#sound-dai-cells = <0>;
		};

		abox_rdma_10: abox-rdma@18c51a00 {
			compatible = "samsung,abox-rdma";
			reg = <0x0 0x18c51a00 0x100>;
			reg-names = "sfr";
			samsung,id = <10>;
			samsung,type = "normal";
			samsung,buffer_type = "dma";
			#sound-dai-cells = <0>;
		};

		abox_rdma_11: abox-rdma@18c51b00 {
			compatible = "samsung,abox-rdma";
			reg = <0x0 0x18c51b00 0x100>;
			reg-names = "sfr";
			samsung,id = <11>;
			samsung,type = "normal";
			samsung,buffer_type = "dma";
			#sound-dai-cells = <0>;
		};

		abox_wdma_0: abox-wdma@18c53000 {
			compatible = "samsung,abox-wdma";
			reg = <0x0 0x18c53000 0x100>;
			reg-names = "sfr";
			samsung,id = <0>;
			samsung,type = "realtime";
			samsung,buffer_type = "dma";
			#sound-dai-cells = <0>;
		};

		abox_wdma_1: abox-wdma@18c53100 {
			compatible = "samsung,abox-wdma";
			reg = <0x0 0x18c53100 0x100>;
			reg-names = "sfr";
			samsung,id = <1>;
			samsung,type = "normal";
			samsung,buffer_type = "ion";
			#sound-dai-cells = <0>;
		};

		abox_wdma_2: abox-wdma@18c53200 {
			compatible = "samsung,abox-wdma";
			reg = <0x0 0x18c53200 0x100>;
			reg-names = "sfr";
			samsung,id = <2>;
			samsung,type = "call";
			samsung,buffer_type = "dma";
			#sound-dai-cells = <0>;
			samsung,asrc-id = <6>;
		};

		abox_wdma_3: abox-wdma@18c53300 {
			compatible = "samsung,abox-wdma";
			reg = <0x0 0x18c53300 0x100>;
			reg-names = "sfr";
			samsung,id = <3>;
			samsung,type = "realtime";
			samsung,buffer_type = "dma";
			#sound-dai-cells = <0>;
		};

		abox_wdma_4: abox-wdma@18c53400 {
			compatible = "samsung,abox-wdma";
			reg = <0x0 0x18c53400 0x100>;
			reg-names = "sfr";
			samsung,id = <4>;
			samsung,type = "vi-sensing";
			samsung,buffer_type = "dma";
			#sound-dai-cells = <0>;
		};

		abox_wdma_5: abox-wdma@18c53500 {
			compatible = "samsung,abox-wdma";
			reg = <0x0 0x18c53500 0x100>;
			reg-names = "sfr";
			samsung,id = <5>;
			samsung,type = "normal";
			samsung,buffer_type = "dma";
			#sound-dai-cells = <0>;
		};

		abox_wdma_6: abox-wdma@18c53600 {
			compatible = "samsung,abox-wdma";
			reg = <0x0 0x18c53600 0x100>;
			reg-names = "sfr";
			samsung,id = <6>;
			samsung,type = "normal";
			samsung,buffer_type = "dma";
			#sound-dai-cells = <0>;
		};

		abox_wdma_7: abox-wdma@18c53700 {
			compatible = "samsung,abox-wdma";
			reg = <0x0 0x18c53700 0x100>;
			reg-names = "sfr";
			samsung,id = <7>;
			samsung,type = "normal";
			samsung,buffer_type = "dma";
			#sound-dai-cells = <0>;
		};

		abox_uaif_0: abox-uaif@18c50500 {
			compatible = "samsung,abox-uaif";
			reg = <0x0 0x18c50500 0x10>;
			reg-names = "sfr";
			id = <0>;
			clocks = <&clock DOUT_CLK_AUD_UAIF0>, <&clock GATE_ABOX_BCLK0>;
			clock-names = "bclk", "bclk_gate";
			pinctrl-names = "default", "sleep";
			pinctrl-0 = <&aud_i2s0_bus>;
			pinctrl-1 = <&aud_i2s0_idle>;
			#sound-dai-cells = <0>;
		};

		abox_uaif_1: abox-uaif@18c50510 {
			compatible = "samsung,abox-uaif";
			reg = <0x0 0x18c50510 0x10>;
			reg-names = "sfr";
			id = <1>;
			clocks = <&clock DOUT_CLK_AUD_UAIF1>, <&clock GATE_ABOX_BCLK1>;
			clock-names = "bclk", "bclk_gate";
			pinctrl-names = "default", "sleep";
			pinctrl-0 = <&aud_i2s1_bus>;
			pinctrl-1 = <&aud_i2s1_idle>;
			#sound-dai-cells = <0>;
		};

		abox_uaif_2: abox-uaif@18c50520 {
			compatible = "samsung,abox-uaif";
			reg = <0x0 0x18c50520 0x10>;
			reg-names = "sfr";
			id = <2>;
			clocks = <&clock DOUT_CLK_AUD_UAIF2>, <&clock GATE_ABOX_BCLK2>;
			clock-names = "bclk", "bclk_gate";
			pinctrl-names = "default", "sleep";
			pinctrl-0 = <&aud_i2s2_bus>;
			pinctrl-1 = <&aud_i2s2_idle>;
			#sound-dai-cells = <0>;
		};

		abox_uaif_3: abox-uaif@18c50530 {
			compatible = "samsung,abox-uaif";
			reg = <0x0 0x18c50530 0x10>;
			reg-names = "sfr";
			id = <3>;
			clocks = <&clock DOUT_CLK_AUD_UAIF3>, <&clock GATE_ABOX_BCLK3>;
			clock-names = "bclk", "bclk_gate";
			pinctrl-names = "default", "sleep";
			pinctrl-0 = <&aud_i2s3_bus>;
			pinctrl-1 = <&aud_i2s3_idle>;
			#sound-dai-cells = <0>;
		};

		abox_dsif: abox-dsif@18c50550 {
			compatible = "samsung,abox-dsif";
			reg = <0x0 0x18c50550 0x10>;
			reg-names = "sfr";
			id = <5>;
			clocks = <&clock DOUT_CLK_AUD_DSIF>, <&clock GATE_ABOX_BCLK_DSIF>;
			clock-names = "bclk", "bclk_gate";
			/* DSIF and UAIF2 shares GPIO
			 * pinctrl-names = "default", "sleep";
			 * pinctrl-0 = <&aud_dsd_bus>;
			 * pinctrl-1 = <&aud_dsd_idle>;
			 */
			#sound-dai-cells = <0>;
		};

		abox_effect: abox-effect@18d2e000 {
			compatible = "samsung,abox-effect";
			reg = <0x0 0x18d2e000 0x1000>;
			reg-names = "reg";
		};

		abox_debug: abox-debug@0 {
			compatible = "samsung,abox-debug";
			memory-region = <&abox_rmem>;
			reg = <0x0 0x0 0x0>;
		};

		abox_vss: abox-vss@0 {
			compatible = "samsung,abox-vss";
			samsung,magic-offset = <0x700000>;
			reg = <0x0 0x0 0x0>;
		};

		ext_bin_0: ext-bin@0 {
			status = "disabled";
			samsung,name = "dummy.bin";
			samsung,area = <1>; /* 0:SRAM, 1:DRAM, 2:VSS */
			samsung,offset = <0x0>;
		};
		ext_bin_1: ext-bin@1 {
			status = "disabled";
			samsung,name = "AP_AUDIO_SLSI.bin";
			samsung,area = <1>;
			samsung,offset = <0x7f0000>;
		};
		ext_bin_2: ext-bin@2 {
			status = "disabled";
			samsung,name = "APBargeIn_AUDIO_SLSI.bin";
			samsung,area = <1>;
			samsung,offset = <0x7ec000>;
		};
		ext_bin_3: ext-bin@3 {
			status = "okay";
			samsung,name = "SoundBoosterParam.bin";
			samsung,area = <1>;
			samsung,offset = <0x4fc000>;
		};
		ext_bin_4: ext-bin@4 {
			status = "okay";
			samsung,name = "APDV_AUDIO_SLSI.bin";
			samsung,area = <1>;
			samsung,offset = <0x4d0000>;
		};
		ext_bin_5: ext-bin@5 {
			status = "disabled";
			samsung,name = "APBiBF_AUDIO_SLSI.bin";
			samsung,area = <1>;
			samsung,offset = <0x7ef000>;
		};
		ext_bin_6: ext-bin@6 {
			status = "okay";
			samsung,name = "dnn.bin";
			samsung,area = <1>;
			samsung,offset = <0x500800>;
		};
		ext_bin_7: ext-bin@7 {
			status = "okay";
			samsung,name = "usbout.bin";
			samsung,area = <1>;
			samsung,offset = <0x1100000>;
		};
		ext_bin_8: ext-bin@8 {
			status = "okay";
			samsung,name = "usbin.bin";
			samsung,area = <1>;
			samsung,offset = <0x1110000>;
		};
		ext_bin_9: ext-bin@9 {
			status = "okay";
			samsung,name = "fmsb.bin";
			samsung,area = <1>;
			samsung,offset = <0x1120000>;
		};
		ext_bin_10: ext-bin@a {
			status = "okay";
			samsung,name = "txse1.bin";
			samsung,area = <1>;
			samsung,offset = <0x1200000>;
		};
		ext_bin_11: ext-bin@b {
			status = "okay";
			samsung,name = "rxse.bin";
			samsung,area = <1>;
			samsung,offset = <0x1300000>;
		};
		ext_bin_12: ext-bin@c {
			status = "okay";
			samsung,name = "txse2.bin";
			samsung,area = <1>;
			samsung,offset = <0x13b0000>;
		};
		ext_bin_13: ext-bin@d {
			status = "okay";
			samsung,name = "a2dpcom.bin";
			samsung,area = <1>;
			samsung,offset = <0x13e2000>;
		};
		ext_bin_14: ext-bin@e {
			status = "disabled";
			samsung,name = "bidirmic.bin";
			samsung,area = <1>;
			samsung,offset = <0x1414000>;
		};
		ext_bin_15: ext-bin@f {
			status = "okay";
			samsung,name = "calliope2.dt";
			samsung,area = <1>;
			samsung,offset = <0x11fe000>;
			samsung,mixer-control;
		};
	};

	speedy: speedy@15970000 {
		compatible = "samsung,exynos-speedy";
		reg = <0x0 0x15970000 0x2000>;
		interrupts = <GIC_SPI INTREQ__SPEEDY_APM IRQ_TYPE_LEVEL_HIGH>;
		#address-cells = <1>;
		#size-cells = <0>;
		pinctrl-names = "default";
		pinctrl-0 = <&speedy_bus>;
		status = "disabled";
	};

	speedy1: speedy1@15980000 {
		compatible = "samsung,exynos-speedy";
		reg = <0x0 0x15980000 0x2000>;
		interrupts = <GIC_SPI INTREQ__SPEEDY_SUB_APM IRQ_TYPE_LEVEL_HIGH>;
		#address-cells = <1>;
		#size-cells = <0>;
		pinctrl-names = "default";
		pinctrl-0 = <&speedy1_bus>;
		status = "disabled";
	};

	exynos-sci {
		compatible = "samsung,exynos-sci";
		acpm-ipc-channel = <10>;
		use_init_llc_region = <1>;
		initial_llc_region = <1>;	/* LLC_REGION_LIT_MID_ALL */
		llc_enable = <1>;
	};

	iommu-domain_dpu {
		compatible = "samsung,exynos-iommu-bus";
		#address-cells = <2>;
		#size-cells = <1>;
		ranges;

		domain-clients = <&dsim_0>, <&dpp_6>;
	};

	dpp_0: dpp@0x19071000 {	/* GF0 */
		compatible = "samsung,exynos9-dpp";
		#pb-id-cells = <3>;
		/* DPU_DMA, DPP, DPU_DMA_COMMON */
		reg = <0x0 0x19071000 0x1000>, <0x0 0x19021000 0x1000>, <0x0 0x19070000 0x110>;
		/* DPU_DMA IRQ, DPP IRQ */
		interrupts = <GIC_SPI INTREQ__DPU_DMA_GF0 IRQ_TYPE_LEVEL_HIGH>,
			     <GIC_SPI INTREQ__DPU_DPP_GF0 IRQ_TYPE_LEVEL_HIGH>;
		/* Each bit indicates DPP attribute */
		/* 0:AFBC 1:BLOCK 2:FLIP 3:ROT 4:CSC 5:SCALE 6:HDR 7:HDR10 */
		/* 16:IDMA 17:ODMA 18:DPP */
		attr = <0x50087>; /* DPP/IDMA/HDR10/FLIP/BLOCK/AFBC */
		port = <0>; /* AXI port number */

		/* HW restriction */
		src_f_w = <16 65534 1>;
		src_f_h = <16 8190 1>;
		src_w = <16 4096 1>;
		src_h = <16 4096 1>;
		src_xy_align = <1 1>;

		dst_f_w = <16 8190 1>;
		dst_f_h = <16 8190 1>;
		dst_w = <16 4096 1>;
		dst_h = <16 4096 1>;
		dst_xy_align = <1 1>;

		blk_w = <4 4096 1>;
		blk_h = <1 4096 1>;
		blk_xy_align = <1 1>;

		src_h_rot_max = <2160>;

		/* 1: scale X, 2: 1/2x scale down, 4: 1/4x scale down */
		scale_down = <1>;
		/* 1: scale X, 2: 2x scale up, 4: 4x scale up */
		scale_up = <1>;

		/* supported format count */
		fmt_cnt = <4>;
		/* supported format list */
		fmt = <DECON_PIXEL_FORMAT_ARGB_2101010 DECON_PIXEL_FORMAT_ABGR_2101010
			DECON_PIXEL_FORMAT_RGBA_1010102 DECON_PIXEL_FORMAT_BGRA_1010102>;
	};

	dpp_1: dpp@0x19076000 {	/* VGRFS */
		compatible = "samsung,exynos9-dpp";
		#pb-id-cells = <3>;
		reg = <0x0 0x19076000 0x1000>, <0x0 0x19026000 0x1000>;
		interrupts = <GIC_SPI INTREQ__DPU_DMA_VGRFS IRQ_TYPE_LEVEL_HIGH>,
			     <GIC_SPI INTREQ__DPU_DPP_VGRFS IRQ_TYPE_LEVEL_HIGH>;
		attr = <0x500FF>; /* DPP/IDMA/HDR10/HDR/SCALE/CSC/FLIP/BLOCK/AFBC */
		port = <0>;
		scale_down = <2>;
		scale_up = <8>;
		fmt_cnt = <21>;
		fmt = <DECON_PIXEL_FORMAT_ARGB_2101010 DECON_PIXEL_FORMAT_ABGR_2101010
			DECON_PIXEL_FORMAT_RGBA_1010102 DECON_PIXEL_FORMAT_BGRA_1010102
			DECON_PIXEL_FORMAT_NV16 DECON_PIXEL_FORMAT_NV61
			DECON_PIXEL_FORMAT_NV12 DECON_PIXEL_FORMAT_NV21
			DECON_PIXEL_FORMAT_NV12M DECON_PIXEL_FORMAT_NV21M
			DECON_PIXEL_FORMAT_NV12N DECON_PIXEL_FORMAT_NV12N_10B
			DECON_PIXEL_FORMAT_NV12M_P010 DECON_PIXEL_FORMAT_NV21M_P010
			DECON_PIXEL_FORMAT_NV12M_S10B DECON_PIXEL_FORMAT_NV21M_S10B
			DECON_PIXEL_FORMAT_NV16M_P210 DECON_PIXEL_FORMAT_NV61M_P210
			DECON_PIXEL_FORMAT_NV16M_S10B DECON_PIXEL_FORMAT_NV61M_S10B
			DECON_PIXEL_FORMAT_NV12_P010>;
	};

	dpp_2: dpp@0x19072000 {	/* GF1 */
		compatible = "samsung,exynos9-dpp";
		#pb-id-cells = <3>;
		reg = <0x0 0x19072000 0x1000>, <0x0 0x19022000 0x1000>;
		interrupts = <GIC_SPI INTREQ__DPU_DMA_GF1 IRQ_TYPE_LEVEL_HIGH>,
			     <GIC_SPI INTREQ__DPU_DPP_GF1 IRQ_TYPE_LEVEL_HIGH>;
		attr = <0x50087>; /* DPP/IDMA/HDR10/FLIP/BLOCK/AFBC */
		port = <1>;
		scale_down = <1>;
		scale_up = <1>;
		fmt_cnt = <4>;
		fmt = <DECON_PIXEL_FORMAT_ARGB_2101010 DECON_PIXEL_FORMAT_ABGR_2101010
			DECON_PIXEL_FORMAT_RGBA_1010102 DECON_PIXEL_FORMAT_BGRA_1010102>;
	};

	dpp_3: dpp@0x19075000 {	/* VGF */
		compatible = "samsung,exynos9-dpp";
		#pb-id-cells = <3>;
		reg = <0x0 0x19075000 0x1000>, <0x0 0x19024000 0x1000>;
		interrupts = <GIC_SPI INTREQ__DPU_DMA_VGF IRQ_TYPE_LEVEL_HIGH>,
			     <GIC_SPI INTREQ__DPU_DPP_VGF IRQ_TYPE_LEVEL_HIGH>;
		attr = <0x50097>; /* DPP/IDMA/HDR10/CSC/FLIP/BLOCK/AFBC */
		port = <1>;
		scale_down = <1>;
		scale_up = <1>;
		fmt_cnt = <21>;
		fmt = <DECON_PIXEL_FORMAT_ARGB_2101010 DECON_PIXEL_FORMAT_ABGR_2101010
			DECON_PIXEL_FORMAT_RGBA_1010102 DECON_PIXEL_FORMAT_BGRA_1010102
			DECON_PIXEL_FORMAT_NV16 DECON_PIXEL_FORMAT_NV61
			DECON_PIXEL_FORMAT_NV12 DECON_PIXEL_FORMAT_NV21
			DECON_PIXEL_FORMAT_NV12M DECON_PIXEL_FORMAT_NV21M
			DECON_PIXEL_FORMAT_NV12N DECON_PIXEL_FORMAT_NV12N_10B
			DECON_PIXEL_FORMAT_NV12M_P010 DECON_PIXEL_FORMAT_NV21M_P010
			DECON_PIXEL_FORMAT_NV12M_S10B DECON_PIXEL_FORMAT_NV21M_S10B
			DECON_PIXEL_FORMAT_NV16M_P210 DECON_PIXEL_FORMAT_NV61M_P210
			DECON_PIXEL_FORMAT_NV16M_S10B DECON_PIXEL_FORMAT_NV61M_S10B
			DECON_PIXEL_FORMAT_NV12_P010>;
	};

	dpp_4: dpp@0x19073000 {	/* VG */
		compatible = "samsung,exynos9-dpp";
		#pb-id-cells = <3>;
		reg = <0x0 0x19073000 0x1000>, <0x0 0x19023000 0x1000>;
		interrupts = <GIC_SPI INTREQ__DPU_DMA_VG IRQ_TYPE_LEVEL_HIGH>,
			     <GIC_SPI INTREQ__DPU_DPP_VG IRQ_TYPE_LEVEL_HIGH>;
		attr = <0x50096>; /* DPP/IDMA/HDR10/CSC/FLIP/BLOCK */
		port = <2>;
		scale_down = <1>;
		scale_up = <1>;
		fmt_cnt = <21>;
		fmt = <DECON_PIXEL_FORMAT_ARGB_2101010 DECON_PIXEL_FORMAT_ABGR_2101010
			DECON_PIXEL_FORMAT_RGBA_1010102 DECON_PIXEL_FORMAT_BGRA_1010102
			DECON_PIXEL_FORMAT_NV16 DECON_PIXEL_FORMAT_NV61
			DECON_PIXEL_FORMAT_NV12 DECON_PIXEL_FORMAT_NV21
			DECON_PIXEL_FORMAT_NV12M DECON_PIXEL_FORMAT_NV21M
			DECON_PIXEL_FORMAT_NV12N DECON_PIXEL_FORMAT_NV12N_10B
			DECON_PIXEL_FORMAT_NV12M_P010 DECON_PIXEL_FORMAT_NV21M_P010
			DECON_PIXEL_FORMAT_NV12M_S10B DECON_PIXEL_FORMAT_NV21M_S10B
			DECON_PIXEL_FORMAT_NV16M_P210 DECON_PIXEL_FORMAT_NV61M_P210
			DECON_PIXEL_FORMAT_NV16M_S10B DECON_PIXEL_FORMAT_NV61M_S10B
			DECON_PIXEL_FORMAT_NV12_P010>;
	};

	dpp_5: dpp@0x19074000 {	/* VGS */
		compatible = "samsung,exynos9-dpp";
		#pb-id-cells = <3>;
		reg = <0x0 0x19074000 0x1000>, <0x0 0x19025000 0x1000>;
		interrupts = <GIC_SPI INTREQ__DPU_DMA_VGS IRQ_TYPE_LEVEL_HIGH>,
			     <GIC_SPI INTREQ__DPU_DPP_VGS IRQ_TYPE_LEVEL_HIGH>;
		attr = <0x500B6>; /* DPP/IDMA/HDR10/SCALE/CSC/FLIP/BLOCK */
		port = <2>;
		scale_down = <2>;
		scale_up = <8>;
		fmt_cnt = <21>;
		fmt = <DECON_PIXEL_FORMAT_ARGB_2101010 DECON_PIXEL_FORMAT_ABGR_2101010
			DECON_PIXEL_FORMAT_RGBA_1010102 DECON_PIXEL_FORMAT_BGRA_1010102
			DECON_PIXEL_FORMAT_NV16 DECON_PIXEL_FORMAT_NV61
			DECON_PIXEL_FORMAT_NV12 DECON_PIXEL_FORMAT_NV21
			DECON_PIXEL_FORMAT_NV12M DECON_PIXEL_FORMAT_NV21M
			DECON_PIXEL_FORMAT_NV12N DECON_PIXEL_FORMAT_NV12N_10B
			DECON_PIXEL_FORMAT_NV12M_P010 DECON_PIXEL_FORMAT_NV21M_P010
			DECON_PIXEL_FORMAT_NV12M_S10B DECON_PIXEL_FORMAT_NV21M_S10B
			DECON_PIXEL_FORMAT_NV16M_P210 DECON_PIXEL_FORMAT_NV61M_P210
			DECON_PIXEL_FORMAT_NV16M_S10B DECON_PIXEL_FORMAT_NV61M_S10B
			DECON_PIXEL_FORMAT_NV12_P010>;
	};

	dpp_6: dpp@0x19077000{
		compatible = "samsung,exynos9-dpp";
		#pb-id-cells = <3>;
		reg = <0x0 0x19077000 0x1000>, <0x0 0x19060000 0x1000>;
		interrupts = <0 INTREQ__DPU_DMA_WB 0>;
		attr = <0xA0010>; /* WBMUX/ODMA/CSC */
		port = <2>;
		scale_down = <1>;
		scale_up = <1>;
		fmt_cnt = <0>;

		/*
		 * dpp_6 is used for writeback. It means dpp_6 becomes
		 * output device of DECON. The output device has to manage
		 * power domain, clock and sysmmu control
		 */
		iommus = <&sysmmu_dpu0>, <&sysmmu_dpu1>, <&sysmmu_dpu2>;
		clock-names = "aclk";
		clocks = <&clock GATE_DPU_DPU>;
	};

	disp_ss: disp_ss@0x16010000 {
		compatible = "samsung,exynos9-disp_ss";
		reg = <0x0 0x19011000 0x10>;
	};

	mipi_phy_dsim0_m4s4_top: dphy_m4s4_dsim0@0x19160000 {
		compatible = "samsung,mipi-phy-m4s4-top";
		isolation = <0x070c>;
		owner = <0>; /* 0: DSI,  1: CSI */
		#phy-cells = <1>;
	};

	mipi_phy_dsim0_m4s0: dphy_m4s0_dsim0@0x19161000 {
		compatible = "samsung,mipi-phy-m4s0";
		isolation = <0x0710>;
		owner = <0>; /* 0: DSI,  1: CSI */
		#phy-cells = <1>;
	};

	dsim_0: dsim@0x19080000 {
		compatible = "samsung,exynos9-dsim";
		reg = <0x0 0x19080000 0x300>, <0x0 0x19161000 0x800>, <0x0 0x19160000 0x100>;
		interrupts = <GIC_SPI INTREQ__DPU_DSIM0 IRQ_TYPE_LEVEL_HIGH>;
		iommus = <&sysmmu_dpu0>, <&sysmmu_dpu1>, <&sysmmu_dpu2>;

		/* clock */
		clock-names = "aclk";
		clocks = <&clock GATE_DPU_DPU>;

		phys = <&mipi_phy_dsim0_m4s0 0>, <&mipi_phy_dsim0_m4s4_top 0>;
		phy-names = "dsim_dphy", "dsim_dphy_extra";
	};

	backlight_0: backlight_0 {
		compatible = "samsung,exynos-backlight";
		max-brightness = <255>;
		min-brightness = <0>;
		dft-brightness = <127>;
		dsim = <&dsim_0>;
	};

	panel_0: panel_0 {
		compatible = "samsung,exynos-panel";
		max-brightness = <255>;
		dft-brightness = <127>;
		ddi_id = <0x244040>;
		lcd_info = <&s6e3ha8>, <&s6e3ha9>, <&s6e3fa0>;
	};

	decon_f: decon_f@0x19030000 {
		compatible = "samsung,exynos9-decon";
		#pb-id-cells = <4>;
		reg = <0x0 0x19030000 0x10000>;

		/* interrupt num : FRAME_START, FRMAE_DONE, EXTRA, GPIO_PERIC1(EXT_INT_TE: GPD0[0]) */
		interrupts = <GIC_SPI INTREQ__DPU_DECON0_FRAME_START IRQ_TYPE_LEVEL_HIGH>,
			     <GIC_SPI INTREQ__DPU_DECON0_FRAME_DONE IRQ_TYPE_LEVEL_HIGH>,
			     <GIC_SPI INTREQ__DPU_DECON0_EXTRA IRQ_TYPE_LEVEL_HIGH>,
			     <GIC_SPI INTREQ__GPIO_PERIC1 IRQ_TYPE_LEVEL_HIGH>;

		/* pinctrl */
		pinctrl-names = "hw_te_on", "hw_te_off";
		pinctrl-0 = <&decon_f_te_on>;
		pinctrl-1 = <&decon_f_te_off>;

		max_win = <6>;
		default_win = <5>;
		default_ch = <0>;
		psr_mode = <2>;         /* 0: video mode, 1: DP command mode, 2: MIPI command mode */
		trig_mode = <0>;        /* 0: hw trigger, 1: sw trigger */
		dsi_mode = <0>;         /* 0: single dsi, 1: dual dsi */

		/* 0: DSI, 1: eDP, 2:HDMI, 3: WB */
		out_type = <0>;
		/* 0: DSI0, 1: DSI1, 2: DSI2 */
		out_idx = <0>;

		/* pixel per clock */
		ppc = <2>;
		line_mem_cnt = <4>;
		cycle_per_line = <8>;   /* 4ppc */

		chip_ver = <9820>;

		dpp_cnt = <6>;
		dsim_cnt = <2>;
		decon_cnt = <3>;

		#address-cells = <2>;
		#size-cells = <1>;
		ranges;

		/* EINT for TE */
		gpios = <&gpd0 0 0xf>;
		/* sw te pending register */
		te_eint {
			/* NWEINT_GPD0_PEND */
			reg = <0x0 0x10830a14 0x4>;
		};

		cam-stat {
			/* ISPPRE_STATUS(0x15862504) */
			reg = <0x0 0x15862504 0x4>;
		};
	};

	decon_s: decon_s@0x19040000 {
		compatible = "samsung,exynos9-decon";
		#pb-id-cells = <4>;
		reg = <0x0 0x19040000 0x10000>;

		/* interrupt num : FRAME_START, FRMAE_DONE, EXTRA, GPIO_PERIC1(EXT_INT_TE: GPD0[0]) */
		interrupts = <0 INTREQ__DPU_DECON1_FRAME_START 0>,
			     <0 INTREQ__DPU_DECON1_FRAME_DONE 0>,
			     <0 INTREQ__DPU_DECON1_EXTRA 0>;

		max_win = <6>;
		default_win = <3>;
		default_ch = <1>;
		psr_mode = <2>;         /* 0: video mode, 1: DP command mode, 2: MIPI command mode */
		trig_mode = <1>;        /* 0: hw trigger, 1: sw trigger */
		dsi_mode = <0>;         /* 0: single dsi, 1: dual dsi */

		/* 0: DSI, 1: eDP, 2:HDMI, 3: WB */
		out_type = <3>;
		/* 0: DSI0, 1: DSI1, 2: DSI2 */
		out_idx = <0>;

		/* pixel per clock */
		ppc = <2>;
		line_mem_cnt = <4>;
		cycle_per_line = <8>;   /* 4ppc */

		chip_ver = <9820>;

		dpp_cnt = <7>;
		dsim_cnt = <2>;
		decon_cnt = <3>;

		#address-cells = <2>;
		#size-cells = <1>;
		ranges;
	};

	iommu-domain_aud {
		compatible = "samsung,exynos-iommu-bus";
		#address-cells = <2>;
		#size-cells = <1>;
		ranges;

		domain-clients = <&abox>;
	};

	fimg2d: g2d@18A20000 {
		compatible = "samsung,exynos9820-g2d";
		reg = <0x0 0x18A20000 0xA000>;
		interrupts = <0 INTREQ__G2D IRQ_TYPE_LEVEL_HIGH>;
		clock-names = "gate";
		clocks = <&clock GATE_G2D>;
		iommus = <&sysmmu_g2d0>, <&sysmmu_g2d1>;
		hw_ppc =
			/* sc_up none x1 x1/4 x1/9 x1/16 */
			<3400 3100 2200 3600 5100 7000 /* rgb32 non-rotated */
			3300 2700 2000 3000 5200 6500 /* rgb32 rotated */
			3000 2900 2600 3400 5100 11900 /* yuv2p non-rotated */
			3200 2000 1900 3300 5200 7000 /* yuv2p rotated */
			2400 1900 1900 2700 3100 4100 /* 8+2 non-rotated */
			2500 900 900 2200 2900 3700 /* 8+2 rotated */
			3800>; /* colorfill */

		g2d_dvfs_table = <534000 711000
				400000 534000
				336000 400000
				267000 356000
				178000 200000
				107000 134000
				>;

		itmon,port = "G2D0", "G2D1";
		itmon,dest = "G2D";
		dma-coherent;
	};

	iommu-domain_g2d {
		compatible = "samsung,exynos-iommu-bus";
		#address-cells = <2>;
		#size-cells = <1>;
		ranges;

		domain-clients = <&fimg2d>;
	};

	iommu-domain_isp {
		compatible = "samsung,exynos-iommu-bus";
		#address-cells = <2>;
		#size-cells = <1>;
		ranges;

		domain-clients = <>;
	};

	iommu-domain_iva {
		compatible = "samsung,exynos-iommu-bus";
		#address-cells = <2>;
		#size-cells = <1>;
		ranges;

		domain-clients = <>;
	};

	iommu-domain_mfc {
		compatible = "samsung,exynos-iommu-bus";
		#address-cells = <2>;
		#size-cells = <1>;
		ranges;

		domain-clients = <&mfc_0>;
	};

	iommu-domain_mscl_smfc {
		compatible = "samsung,exynos-iommu-bus";
		#address-cells = <2>;
		#size-cells = <1>;
		ranges;

		domain-clients = <&scaler_0>, <&smfc>;
	};

	scaler_0: scaler@18B10000 {
		compatible = "samsung,exynos5-scaler";
		reg = <0x0 0x18B10000 0x3000>;
		interrupts = <0 INTREQ__MSCL IRQ_TYPE_LEVEL_HIGH>;
		clocks = <&clock GATE_MSCL>;
		clock-names = "gate";
		itmon,master = "MSCL";
		itmon,dest = "G2D";
		iommus = <&sysmmu_g2d2>;
	};

	smfc: smfc@18B00000 {
		compatible = "samsung,exynos8890-jpeg";
		dma-coherent;
		reg = <0x0 0x18B00000 0x1000>;
		interrupts = <0 INTREQ__JPEG IRQ_TYPE_LEVEL_HIGH>;
		clocks = <&clock GATE_JPEG>;
		clock-names = "gate";
		iommus = <&sysmmu_g2d2>;
		smfc,int_qos_minlock = <534000>;
	};

	iommu-domain_score {
		compatible = "samsung,exynos-iommu-bus";
		#address-cells = <2>;
		#size-cells = <1>;
		ranges;

		domain-clients = <>;
	};

	iommu-domain_npu {
		compatible = "samsung,exynos-iommu-bus";
		#address-cells = <2>;
		#size-cells = <1>;
		ranges;

		domain-clients = <>;
	};

	s2d: exynos_adv_tracer_s2d {
		compatible = "samsung,exynos-adv-tracer-s2d";
		plugin-len = <3>;
		plugin-name = "S2D";
		status = "ok";
	};

	/* mali */
    mali: mali@18500000 {
        compatible = "arm,mali";
        reg = <0x0 0x18500000 0x5000>;
		interrupts = <GIC_SPI INTREQ__G3D_IRQJOB IRQ_TYPE_LEVEL_HIGH>,
					<GIC_SPI INTREQ__G3D_IRQMMU IRQ_TYPE_LEVEL_HIGH>,
					<GIC_SPI INTREQ__G3D_IRQGPU IRQ_TYPE_LEVEL_HIGH>;
        interrupt-names = "JOB", "MMU", "GPU";
        g3d_cmu_cal_id = <ACPM_DVFS_G3D>;
	power-domains = <&pd_embedded_g3d>;
        #cooling-cells = <2>; /* min followed by max */
		governor = "dynamic";
		interactive_info = <377000 94 0>;
		gpu_dvfs_table_size = <9 8>; /*<row col>*/
		/*  8 columns      freq  down   up  stay  mif    little  middle   big  */
		gpu_dvfs_table = <  702000    89  100   9  2093000 1456000       0 1820000
		                    650000    70   97   9  2093000 1456000       0 1664000
		                    572000    60   80   5  1794000 1456000       0       0
		                    433000    65   78   1  1352000       0       0       0
		                    377000    58   79   1  1352000       0       0       0
		                    325000    69   74   1  1014000       0       0       0
		                    260000    61   90   1   676000       0       0       0
		                    200000    62   90   1   676000       0       0       0
		                    156000     0   80   1   676000       0       0       0 >;
		gpu_sustainable_info = <433000 95 949000 1690000 520000>;
		gpu_pmqos_cpu_cluster_num = <3>;
		gpu_pmu_status_reg_offset = <0x2104>;
		gpu_pmu_status_local_pwr_mask = <0x1>; /*0x1 << 0*/
		gpu_max_clock = <702000>;
		gpu_max_clock_limit = <702000>;
		gpu_min_clock = <156000>;
		gpu_dvfs_start_clock = <260000>;
		gpu_dvfs_bl_config_clock = <156000>;
		gpu_default_voltage = <800000>;
		gpu_cold_minimum_vol = <0>;
		gpu_voltage_offset_margin = <37500>;
		gpu_tmu_control = <1>;
		gpu_temp_throttling_level_num = <6>;
		gpu_temp_throttling = <650000 572000 455000 325000 260000 156000>;
		gpu_power_coeff = <625>;
		gpu_dvfs_time_interval = <5>; /*1 tick : 10ms*/
		gpu_default_wakeup_lock = <1>;
		gpu_bus_devfreq = <1>;
		gpu_dynamic_abb = <0>;
		gpu_early_clk_gating = <0>;
		gpu_dvs = <0>;
		gpu_inter_frame_pm = <1>;
		gpu_perf_gathering = <0>;
		gpu_runtime_pm_delay_time = <50>;
		gpu_dvfs_polling_time = <30>;
		gpu_pmqos_int_disable = <1>;
		gpu_pmqos_mif_max_clock = <2094000>;
		gpu_pmqos_mif_max_clock_base = <650000>;
		gpu_cl_dvfs_start_base = <377000>;
		gpu_debug_level = <3>; /*DEBUG(1) INFO(2) WARNING(3) ERROR(4)*/
		gpu_trace_level = <8>; /*TRACE_ALL*/
		gpu_mo_min_clock = <377000>;
		gpu_boost_gpu_min_lock = <0>;
		gpu_boost_egl_min_lock = <1872000>;
		gpu_vk_boost_max_lock = <325000>;
		gpu_vk_boost_mif_min_lock = <1014000>;
	 };


	reboot {
		compatible = "exynos,reboot";
		pmu_base = <0x15860000>;
	};

	udc: usb@10C00000 {
		compatible = "samsung,exynos-dwusb";
		clocks = <&clock GATE_USB31DRD_SLV_LINK>, <&clock USB31DRD>;
		clock-names = "aclk", "sclk";
		reg = <0x0 0x10C00000 0x10000>;
		#address-cells = <2>;
		#size-cells = <1>;
		ranges;
		power-domains = <&pd_fsys0a>;
		status = "okay";

		usbdrd_dwc3: dwc3 {
			compatible = "synopsys,dwc3";
			reg = <0x0 0x10C00000 0x10000>;
			interrupts = <GIC_SPI INTREQ__USB31DRD_GIC_0 IRQ_TYPE_LEVEL_HIGH>;
			tx-fifo-resize = <0>;
			adj-sof-accuracy = <0>;
			is_not_vbus_pad = <1>;
			enable_sprs_transfer = <1>;
			phys = <&usbdrd_phy0 0>, <&usbdrd_phy0 1>;
			phy-names = "usb2-phy", "usb3-phy";
			/* check susphy support */
			xhci_l2_support = <1>;
			dr_mode = "otg";
			/* support usb audio offloading: 1, if not: 0 */
			usb_audio_offloading = <1>;
			/* support USB L2 sleep */
			ldos = <3>;
			ldo_number = <10 11 12>;
			/* INT min lock support */
			usb-pm-qos-int = <400000>;
		};
	};

	usbdrd_phy0: phy@10B00000 {
		compatible = "samsung,exynos-usbdrd-phy";
		reg = <0x0 0x10B00000 0x200>,
			<0x0 0x10AE0000 0x2800>,
			<0x0 0x10AF0000 0x800>;
		interrupts = <GIC_SPI INTREQ__USB2_REMOTE_WAKEUP_GIC IRQ_TYPE_LEVEL_HIGH>,
			     <GIC_SPI INTREQ__USB2_REMOTE_CONNECT_GIC IRQ_TYPE_LEVEL_HIGH>;
		clocks = <&clock OSCCLK>, <&clock GATE_USB31DRD_SLV_LINK>;
		clock-names = "ext_xtal", "aclk";
		samsung,pmu-syscon = <&pmu_system_controller>;
		pmu_mask = <0x0>;
		pmu_offset = <0x72c>;
		pmu_offset_dp = <0x704>;
		/* USBDP combo phy version  - 0x200 */
		phy_version = <0x301>;
		/* if it doesn't need phy user mux, */
		/*  you should write "none" */
		/*  but refclk shouldn't be omitted */
		phyclk_mux = "none";
		phy_refclk = "ext_xtal";

		/* if Main phy has the other phy, it must be set to 1. jusf for usbphy_info */
		has_other_phy = <0>;
		/* if combo phy is used, it must be set to 1. usbphy_sub_info is enabled */
		has_combo_phy = <1>;
		sub_phy_version = <0x400>;

		/* ip type */
		/* USB3DRD = 0 */
		/*  USB3HOST = 1 */
		/*  USB2DRD = 2 */
		/*  USB2HOST = 3 */
		ip_type = <0x0>;

		/* for PHY CAL */
		/* choice only one item */
		phy_refsel_clockcore = <1>;
		phy_refsel_ext_osc = <0>;
		phy_refsel_xtal = <0>;
		phy_refsel_diff_pad = <0>;
		phy_refsel_diff_internal = <0>;
		phy_refsel_diff_single = <0>;

		/* true : 1 , false : 0 */
		use_io_for_ovc = <0>;
		common_block_disable = <1>;
		is_not_vbus_pad = <1>;
		used_phy_port = <0>;

		status = "okay";

		#phy-cells = <1>;
		ranges;
	};

	usb_notifier {
		compatible = "samsung,usb-notifier";
		udc = <&udc>;
	};

	/* DMA */
	amba {
		#address-cells = <2>;
		#size-cells = <1>;
		compatible = "arm,amba-bus";
		interrupt-parent = <&gic>;
		ranges;
		pdma0: pdma0@1A2E0000 {
			compatible = "arm,pl330", "arm,primecell";
			reg = <0x0 0x1A2E0000 0x1000>;
			interrupts = <GIC_SPI INTREQ__PDMA0 IRQ_TYPE_LEVEL_HIGH>;
			clocks = <&clock GATE_PDMA0>;
			clock-names = "apb_pclk";
			#dma-cells = <1>;
			#dma-channels = <8>;
			#dma-requests = <32>;
			#dma-multi-irq = <1>;
			dma-arwrapper = <0x1A2E4400>,
					<0x1A2E4420>,
					<0x1A2E4440>,
					<0x1A2E4460>,
					<0x1A2E4480>,
					<0x1A2E44A0>,
					<0x1A2E44C0>,
					<0x1A2E44E0>;
			dma-awwrapper = <0x1A2E4404>,
					<0x1A2E4424>,
					<0x1A2E4444>,
					<0x1A2E4464>,
					<0x1A2E4484>,
					<0x1A2E44A4>,
					<0x1A2E44C4>,
					<0x1A2E44E4>;
			dma-instwrapper = <0x1A2E4500>;
			dma-mask-bit = <36>;
			coherent-mask-bit = <36>;
		};
	};

	watchdog_cl0@10050000 {
		compatible = "samsung,exynos9-v1-wdt";
		reg = <0x0 0x10050000 0x100>;
		interrupts = <GIC_SPI INTREQ__WDT_CLUSTER0 IRQ_TYPE_LEVEL_HIGH>;
		clocks = <&clock OSCCLK>, <&clock GATE_WDT_CLUSTER0>;
		clock-names = "rate_watchdog", "gate_watchdog";
		timeout-sec = <30>;
		samsung,syscon-phandle = <&pmu_system_controller>;
		index = <0>; /* if little cluster then index is 0*/
	};

	watchdog_cl2@10060000 {
		compatible = "samsung,exynos9-v2-wdt";
		reg = <0x0 0x10060000 0x100>;
		interrupts = <GIC_SPI INTREQ__WDT_CLUSTER2 IRQ_TYPE_LEVEL_HIGH>;
		clocks = <&clock OSCCLK>, <&clock GATE_WDT_CLUSTER2>;
		clock-names = "rate_watchdog", "gate_watchdog";
		timeout-sec = <30>;
		samsung,syscon-phandle = <&pmu_system_controller>;
		index = <1>; /* if little cluster then index is 0*/
		use_multistage_wdt; /* Use FIQ debug watchdog */
	};

	exynos-bcmdbg {
		compatible = "samsung,exynos-bcm_dbg";

		pd-name = "pd-trex", "pd-aud", "pd-dpu", "pd-dspm", "pd-fsys0",
			  "pd-fsys1", "pd-g2d", "pd-embedded_g3d", "pd-isphq", "pd-isplp",
			  "pd-isppre", "pd-iva", "pd-mfc", "pd-npu0", "pd-vra2";

		max_define_event = <PRE_DEFINE_EVT_MAX>;
		/* define_event_index ev0 ev1 ev2 ev3 ev4 ev5 ev6 ev7 */
		define_events = <NO_PRE_DEFINE_EVT	0x0  0x0  0x0  0x0  0x0  0x0  0x0  0x0>,
				<LATENCY_FMT_EVT	0x4  0x2  0x26 0x24 0x5  0x3  0x27 0x25>,
				<MO_FMT_EVT		0x4  0x0  0x24 0x24 0x5  0x1  0x25 0x25>,
				<BURST_LENGTH_FMT_EVT	0x4  0x2  0x4  0x26 0x5  0x3  0x5  0x27>,
				<REQ_BLOCK_FMT_EVT	0x2  0x10 0x10 0x26 0x3  0x11 0x11 0x27>,
				<DATA_BLOCK_FMT_EVT	0x4  0x12 0x12 0x6  0x5  0x13 0x13 0x14>,
				<REQ_TYPE_FMT_EVT	0x2  0x15 0x18 0x1B 0x3  0x16 0x19 0x1C>;
		default_define_event = <LATENCY_FMT_EVT>;

		/* sm_id_mask sm_id_value */
		define_filter_id = <NO_PRE_DEFINE_EVT	0x0  0x0>,
				<LATENCY_FMT_EVT	0x0  0x0>,
				<MO_FMT_EVT		0x0  0x0>,
				<BURST_LENGTH_FMT_EVT	0x0  0x0>,
				<REQ_BLOCK_FMT_EVT	0x0  0x0>,
				<DATA_BLOCK_FMT_EVT	0x0  0x0>,
				<REQ_TYPE_FMT_EVT	0x0  0x0>;
		/* ev0 ev1 ev2 ev3 ev4 ev5 ev6 ev7 */
		define_filter_id_active = <NO_PRE_DEFINE_EVT	0x0  0x0  0x0  0x0  0x0  0x0  0x0  0x0>,
					<LATENCY_FMT_EVT	0x0  0x0  0x0  0x0  0x0  0x0  0x0  0x0>,
					<MO_FMT_EVT		0x0  0x0  0x0  0x0  0x0  0x0  0x0  0x0>,
					<BURST_LENGTH_FMT_EVT	0x0  0x0  0x0  0x0  0x0  0x0  0x0  0x0>,
					<REQ_BLOCK_FMT_EVT	0x0  0x0  0x0  0x0  0x0  0x0  0x0  0x0>,
					<DATA_BLOCK_FMT_EVT	0x0  0x0  0x0  0x0  0x0  0x0  0x0  0x0>,
					<REQ_TYPE_FMT_EVT	0x0  0x0  0x0  0x0  0x0  0x0  0x0  0x0>;
		/* sm_other_type0 sm_other_mask0 sm_other_value0 */
		define_filter_other_0 = <NO_PRE_DEFINE_EVT	0x0  0x0  0x0>,
					<LATENCY_FMT_EVT	0x0  0x0  0x0>,
					<MO_FMT_EVT		0x0  0x0  0x0>,
					<BURST_LENGTH_FMT_EVT	0x0  0x0  0x0>,
					<REQ_BLOCK_FMT_EVT	0x0  0x0  0x0>,
					<DATA_BLOCK_FMT_EVT	0x0  0x0  0x0>,
					<REQ_TYPE_FMT_EVT	0x0  0x0  0x0>;
		/* sm_other_type1 sm_other_mask1 sm_other_value1 */
		define_filter_other_1 = <NO_PRE_DEFINE_EVT	0x0  0x0  0x0>,
					<LATENCY_FMT_EVT	0x0  0x0  0x0>,
					<MO_FMT_EVT		0x0  0x0  0x0>,
					<BURST_LENGTH_FMT_EVT	0x0  0x0  0x0>,
					<REQ_BLOCK_FMT_EVT	0x0  0x0  0x0>,
					<DATA_BLOCK_FMT_EVT	0x0  0x0  0x0>,
					<REQ_TYPE_FMT_EVT	0x0  0x0  0x0>;
		/* ev0 ev1 ev2 ev3 ev4 ev5 ev6 ev7 */
		define_filter_other_active = <NO_PRE_DEFINE_EVT	0x0  0x0  0x0  0x0  0x0  0x0  0x0  0x0>,
					<LATENCY_FMT_EVT	0x0  0x0  0x0  0x0  0x0  0x0  0x0  0x0>,
					<MO_FMT_EVT		0x0  0x0  0x0  0x0  0x0  0x0  0x0  0x0>,
					<BURST_LENGTH_FMT_EVT	0x0  0x0  0x0  0x0  0x0  0x0  0x0  0x0>,
					<REQ_BLOCK_FMT_EVT	0x0  0x0  0x0  0x0  0x0  0x0  0x0  0x0>,
					<DATA_BLOCK_FMT_EVT	0x0  0x0  0x0  0x0  0x0  0x0  0x0  0x0>,
					<REQ_TYPE_FMT_EVT	0x0  0x0  0x0  0x0  0x0  0x0  0x0  0x0>;

		/* peak_mask peak_id */
		define_sample_id = <NO_PRE_DEFINE_EVT	0x0  0x0>,
				<LATENCY_FMT_EVT	0x0  0x0>,
				<MO_FMT_EVT		0x0  0x0>,
				<BURST_LENGTH_FMT_EVT	0x0  0x0>,
				<REQ_BLOCK_FMT_EVT	0x0  0x0>,
				<DATA_BLOCK_FMT_EVT	0x0  0x0>,
				<REQ_TYPE_FMT_EVT	0x0  0x0>;
		/* ev0 ev1 ev2 ev3 ev4 ev5 ev6 ev7 */
		define_sample_id_enable = <NO_PRE_DEFINE_EVT	0x0  0x0  0x0  0x0  0x0  0x0  0x0  0x0>,
					<LATENCY_FMT_EVT	0x0  0x0  0x1  0x0  0x0  0x0  0x1  0x0>,
					<MO_FMT_EVT		0x0  0x0  0x1  0x0  0x0  0x0  0x1  0x0>,
					<BURST_LENGTH_FMT_EVT	0x0  0x0  0x1  0x1  0x0  0x0  0x1  0x1>,
					<REQ_BLOCK_FMT_EVT	0x0  0x0  0x1  0x1  0x0  0x0  0x1  0x1>,
					<DATA_BLOCK_FMT_EVT	0x0  0x0  0x1  0x0  0x0  0x0  0x1  0x0>,
					<REQ_TYPE_FMT_EVT	0x0  0x0  0x0  0x0  0x0  0x0  0x0  0x0>;

		bcm_ip_nr = <50>;
		initial_run_bcm_ip = <1>, <2>, <3>, <4>, <5>, <6>, <7>, <8>, <9>, <10>,
				<11>, <12>, <13>, <14>, <15>, <16>, <17>, <18>,	<19>, <20>,
				<21>, <22>, <23>, <24>, <25>, <26>, <27>, <28>, <29>, <30>,
				<31>, <32>, <33>, <34>, <35>, <36>, <37>, <38>, <39>, <40>,
				<41>, <42>, <43>, <44>, <45>, <46>, <47>, <48>, <49>;
		initial_bcm_run = <BCM_STOP>;
		/* msec (max 500msec) */
		initial_period = <1>;
		initial_bcm_mode = <BCM_MODE_INTERVAL>;
		available_stop_owner = <PANIC_HANDLE CAMERA_DRIVER MODEM_IF ITMON_HANDLE>;
		buff_size = <0x100000>;

		ipc_bcm_event {
			plugin-len = <5>;
			plugin-name = "BCM";
		};
	};

	exynos_dm: exynos-dm@17000000 {
		compatible = "samsung,exynos-dvfs-manager";
		reg = <0x0 0x17000000 0x0>;
		acpm-ipc-channel = <1>;
		dm_domains {
			cpufreq_cl0 {
				dm-index = <DM_CPU_CL0>;
				available = "true";
				cal_id = <ACPM_DVFS_CPUCL0>;
				dm_type_name = "dm_cpu_cl0";
			};
			cpufreq_cl1 {
				dm-index = <DM_CPU_CL1>;
				available = "true";
				cal_id = <ACPM_DVFS_CPUCL1>;
				dm_type_name = "dm_cpu_cl1";
			};
			cpufreq_cl2 {
				dm-index = <DM_CPU_CL2>;
				available = "true";
				cal_id = <ACPM_DVFS_CPUCL2>;
				dm_type_name = "dm_cpu_cl2";
			};
			devfreq_mif {
				dm-index = <DM_MIF>;
				available = "true";
				policy_use = "true";
				cal_id = <ACPM_DVFS_MIF>;
				dm_type_name = "dm_mif";
			};
			devfreq_int {
				dm-index = <DM_INT>;
				available = "true";
				policy_use = "true";
				cal_id = <ACPM_DVFS_INT>;
				dm_type_name = "dm_int";
			};
			devfreq_intcam {
				dm-index = <DM_INTCAM>;
				available = "true";
				cal_id = <ACPM_DVFS_INTCAM>;
				dm_type_name = "dm_intcam";
			};
			devfreq_cam {
				dm-index = <DM_CAM>;
				available = "true";
				cal_id = <ACPM_DVFS_CAM>;
				dm_type_name = "dm_cam";
			};
			devfreq_iva {
				dm-index = <DM_IVA>;
				available = "true";
				cal_id = <ACPM_DVFS_IVA>;
				dm_type_name = "dm_iva";
			};
			devfreq_score {
				dm-index = <DM_SCORE>;
				available = "true";
				cal_id = <ACPM_DVFS_SCORE>;
				dm_type_name = "dm_score";
			};
			devfreq_disp {
				dm-index = <DM_DISP>;
				available = "true";
				cal_id = <ACPM_DVFS_DISP>;
				dm_type_name = "dm_disp";
			};
			devfreq_aud {
				dm-index = <DM_AUD>;
				available = "true";
				cal_id = <ACPM_DVFS_AUD>;
				dm_type_name = "dm_aud";
			};
			devfreq_mfc {
				dm-index = <DM_MFC>;
				available = "true";
				cal_id = <ACPM_DVFS_MFC>;
				dm_type_name = "dm_mfc";
			};
			devfreq_NPU {
				dm-index = <DM_NPU>;
				available = "true";
				cal_id = <ACPM_DVFS_NPU>;
				dm_type_name = "dm_npu";
			};
			dvfs_gpu {
				dm-index = <DM_GPU>;
				available = "false";
				cal_id = <ACPM_DVFS_G3D>;
				dm_type_name = "dm_gpu";
			};
		};
	};

	schedutil_gov {
		schedutil_domain0: domain@0 {
			device_type = "schedutil-domain";
			shared-cpus = "0-3";

			enabled = <0>;          /* Disabled */
			qos_min_class = <3>;
		};

		schedutil_domain1: domain@1 {
			device_type = "schedutil-domain";
			shared-cpus = "4-5";

			enabled = <1>;          /* Enabled */
			expired_time = <80>;    /* 80ms */
			qos_min_class = <5>;
		};

		schedutil_domain2: domain@2 {
			device_type = "schedutil-domain";
			shared-cpus = "6-7";

			enabled = <1>;          /* Enabled */
			expired_time = <80>;    /* 80ms */
			qos_min_class = <7>;
		};
	};

	cpufreq {
		cpufreq_domain0: domain@0 {
			device_type = "cpufreq-domain";
			sibling-cpus = "0-3";
			cal-id = <ACPM_DVFS_CPUCL0>;
			dm-type = <DM_CPU_CL0>;

			max-freq = <1950000>;
			min-freq = <442000>;

			/* PM QoS Class ID*/
			pm_qos-min-class = <3>;
			pm_qos-max-class = <4>;

			user-default-qos = <806000>;
			user-boost = <0>;

			#cooling-cells = <2>; /* min followed by max */

			dm-constraints {
				mif-perf {
					const-type = <CONSTRAINT_MIN>;
					dm-type = <DM_MIF>;
					/*  cpu     mif  */
					table = < 1950000  0
						1846000  0
						1742000  0
						1586000  0
						1456000  0
						1300000  0
						1157000  0
						1053000  0
						949000  0
						806000  0
						650000  0
						546000  0
						442000       0
						>;
				};
			};
		};

		cpufreq_domain1: domain@1 {
			device_type = "cpufreq-domain";
			sibling-cpus = "4-5";
			cal-id = <ACPM_DVFS_CPUCL1>;
			dm-type = <DM_CPU_CL1>;

			max-freq = <2314000>;
			min-freq = <507000>;

			/* PM QoS Class ID*/
			pm_qos-min-class = <5>;
			pm_qos-max-class = <6>;

			user-default-qos = <845000>;
			user-boost = <1>;

			#cooling-cells = <2>; /* min followed by max */

			dm-constraints {
				mif-perf {
					const-type = <CONSTRAINT_MIN>;
					dm-type = <DM_MIF>;
					/*  cpu     mif  */
					table = < 2314000  2093000
						2210000      0
						2106000      0
						2002000      0
						1898000      0
						1794000      0
						1690000      0
						1586000      0
						1508000      0
						1404000      0
						1222000      0
						1066000      0
						962000       0
						845000       0
						754000       0
						650000       0
						>;
				};
				ank-perf {
					const-type = <CONSTRAINT_MIN>;
					dm-type = <DM_CPU_CL0>;
					/*  pmt     ank  */
					table = < 2314000  1300000
						2210000  1157000
						2106000  1157000
						2002000  1053000
						1898000  1053000
						1794000  949000
						1690000  949000
						1586000  806000
						1508000  806000
						1404000  806000
						1222000  650000
						1066000  650000
						962000        0
						845000        0
						754000        0
						650000        0
						>;
				};
			};
		};

		cpufreq_domain2: domain@2 {
			device_type = "cpufreq-domain";
			sibling-cpus = "6-7";
			cal-id = <ACPM_DVFS_CPUCL2>;
			dm-type = <DM_CPU_CL2>;
			need-awake;

			max-freq = <2080000>;
			min-freq = <520000>;

			/* PM QoS Class ID*/
			pm_qos-min-class = <7>;
			pm_qos-max-class = <8>;

			user-default-qos = <936000>;
			user-boost = <2>;
			user-sync-min-qos = <2080000>;
			user-sync-max-qos = <1144000>;
			user-sync-qos = <140>;

			#cooling-cells = <2>; /* min followed by max */

			dm-constraints {
				mif-perf {
					const-type = <CONSTRAINT_MIN>;
					dm-type = <DM_MIF>;
					/*  cpu     mif  */
					table = < 2912000  2093000
						2808000  2093000
						2730000  2093000
						2600000  2093000
						2470000  2093000
						2340000  2093000
						2236000  2093000
						2080000  2093000
						1976000        0
						1820000        0
						1664000        0
						1560000        0
						1456000        0
						1378000        0
						1248000        0
						1144000        0
						1040000        0
						936000       0
						819000       0
						728000       0
						624000       0
						520000	     0
						>;
				};
				mif-skew {
					guidance;
					const-type = <CONSTRAINT_MIN>;
					dm-type = <DM_MIF>;
					ect-name = "dvfs_cpucl2";
				};
			};
		};
	};

	exynos-hiu {
		compatible = "samsung,exynos-hiu";
		interrupts = <GIC_SPI INTREQ__CPUCL2_GCUIRQ IRQ_TYPE_LEVEL_HIGH>;
		boot-freq = <1378000>;
		boost-threshold = <2080000>;
		cal-id = <ACPM_DVFS_CPUCL2>;
		sw-pbl = <0x57>;
		bl1-inc = <0>;
		bl2-inc = <0>;
		bl3-inc = <0>;
		tb-enabled;
		pc-enabled;
		operation-mode = <0>;
		sibling-cpus = "6-7";
			     /* PB  BL  PBL  PWR_THR_INC */
		config-table = <0x0 0x0 0x57 0x0        /* config A */
				0x1 0x2 0x79 0x0        /* config B */
				0x0 0x0 0x57 0x0        /* config C */
				0x0 0x0 0x57 0x0        /* config D */
				0x1 0x2 0x79 0x0        /* config E */
				0x0 0x0 0x57 0x0        /* config F */
				0x0 0x0 0x57 0x0        /* config G */
				0x1 0x2 0x79 0x0>;      /* config H */
                 bl1-tbpwr-threshold = <0x0 0x0 0x3 0xFFFF>;
                 bl2-tbpwr-threshold = <0x0 0x0 0x3 0xFFFF>;
	};

	exynos-ocp {
		compatible = "samsung,exynos-ocp";

		interrupts = <GIC_SPI INTREQ__CPUCL2_GCUIRQ IRQ_TYPE_LEVEL_HIGH>;

		sibling-cpus = "6-7";
		down-step = <1>;

		max-freq-wo-ocp = <2080000>;

		release-mode = <1>;             /* 0 : current meter, 1 : cpu utilization */
		release-threshold = <50>;       /* @current meter : current(A), @cpu load : capacity ratio(%) */
		release-duration = <15>;        /* msec */
	};

	exynos_devfreq {
		compatible = "samsung,exynos-devfreq-root";
		#address-cells = <2>;
		#size-cells = <1>;
		ranges;
		devfreq_0: devfreq_mif@17000010 {
			compatible = "samsung,exynos-devfreq";
			reg = <0x0 0x17000010 0x0>;
			devfreq_type = <DEVFREQ_MIF>;
			devfreq_domain_name = "dvfs_mif";
			pm_qos_class = <15>; /* PM_QOS_BUS_THROUGHPUT */
			pm_qos_class_max = <16>; /* PM_QOS_BUS_THROUGHPUT_MAX */
			ess_flag = <ESS_FLAG_MIF>;
			dm-index = <DM_MIF>;

			/* Delay time */
			use_delay_time = "true";
			delay_time_list = "20";

			freq_info = <2094000 421000 421000 421000 2094000 421000>;
			/* initial_freq, default_qos, suspend_freq, min_freq, max_freq reboot_freq */

			/* Booting value */
			boot_info = <40 2093000>;
			/* boot_qos_timeout, boot_freq */

			/* governor data */
			governor = <SIMPLE_INTERACTIVE>;

			bts_update = "true";
			dfs_id = <ACPM_DVFS_MIF>;
			acpm-ipc-channel = <1>;
			use_acpm = "true";
			update_fvp = "true";
		};

		devfreq_1: devfreq_int@17000020 {
			compatible = "samsung,exynos-devfreq";
			reg = <0x0 0x17000020 0x0>;
			devfreq_type = <DEVFREQ_INT>;
			devfreq_domain_name = "dvfs_int";
			pm_qos_class = <11>; /* PM_QOS_DEVICE_THROUGHPUT */
			pm_qos_class_max = <13>; /* PM_QOS_DEVICE_THROUGHPUT_MAX */
			ess_flag = <ESS_FLAG_INT>;
			dm-index = <DM_INT>;

			/* Delay time */
			use_delay_time = "false";

			freq_info = <534000 100000 100000 100000 534000 534000>;
			/* <initial_freq, default_qos, suspend_freq, min, max, reboot_freq> */

			/* Booting value */
			boot_info = <40 534000>;
			/* boot_qos_timeout, boot_freq */

			/* governor data */
			governor = <SIMPLE_INTERACTIVE>;

			bts_update = "false";
			dfs_id = <ACPM_DVFS_INT>;
			acpm-ipc-channel = <1>;
			use_acpm = "true";
		};

		devfreq_2: devfreq_intcam@17000030 {
			compatible = "samsung,exynos-devfreq";
			reg = <0x0 0x17000030 0x0>;
			devfreq_type = <DEVFREQ_INTCAM>;
			devfreq_domain_name = "dvfs_intcam";
			pm_qos_class = <12>; /* PM_QOS_INTCAM_THROUGHPUT */
			pm_qos_class_max = <14>; /* PM_QOS_INTCAM_THROUGHPUT_MAX */
			ess_flag = <ESS_FLAG_INTCAM>;
			dm-index = <DM_INTCAM>;

			/* Delay time */
			use_delay_time = "false";

			freq_info = <690000 650000 650000 650000 690000 690000>;
			/* <initial_freq, default_qos, suspend_freq, min, max, reboot_freq> */

			/* Booting value */
			boot_info = <40 650000>;
			/* boot_qos_timeout, boot_freq */

			/* governor data */
			governor = <SIMPLE_INTERACTIVE>;

			bts_update = "false";
			dfs_id = <ACPM_DVFS_INTCAM>;
		};

		devfreq_3: devfreq_disp@17000040 {
			compatible = "samsung,exynos-devfreq";
			reg = <0x0 0x17000040 0x0>;
			devfreq_type = <DEVFREQ_DISP>;
			devfreq_domain_name = "dvfs_disp";
			pm_qos_class = <19>; /* PM_QOS_DISPLAY_THROUGHPUT */
			pm_qos_class_max = <20>; /* PM_QOS_DISPLAY_THROUGHPUT_MAX */
			ess_flag = <ESS_FLAG_DISP>;
			dm-index = <DM_DISP>;

			/* Delay time */
			use_delay_time = "false";

			freq_info = <640000 134000 134000 134000 640000 640000>;
			/* <initial_freq, default_qos, suspend_freq, min, max, reboot_freq> */

			/* Booting value */
			boot_info = <40 640000>;
			/* boot_qos_timeout, boot_freq */

			/* governor data */
			governor = <SIMPLE_INTERACTIVE>;

			bts_update = "false";
			dfs_id = <ACPM_DVFS_DISP>;
		};

		devfreq_4: devfreq_cam@17000050 {
			compatible = "samsung,exynos-devfreq";
			reg = <0x0 0x17000050 0x0>;
			devfreq_type = <DEVFREQ_CAM>;
			devfreq_domain_name = "dvfs_cam";
			pm_qos_class = <21>; /* PM_QOS_CAM_THROUGHPUT */
			pm_qos_class_max = <26>; /* PM_QOS_CAM_THROUGHPUT_MAX */
			ess_flag = <ESS_FLAG_ISP>;
			dm-index = <DM_CAM>;

			/* Delay time */
			use_delay_time = "false";

			freq_info = <690000 650000 650000 650000 690000 690000>;
			/* <initial, default_qos, suspend_freq, min, max, reboot_freq> */

			/* Booting value */
			boot_info = <40 650000>;
			/* boot_qos_timeout, boot_freq */

			/* governor data */
			governor = <SIMPLE_INTERACTIVE>;

			bts_update = "false";

			dfs_id = <ACPM_DVFS_CAM>;
		};

		devfreq_5: devfreq_aud@17000060 {
			compatible = "samsung,exynos-devfreq";
			reg = <0x0 0x17000060 0x0>;
			devfreq_type = <DEVFREQ_AUD>;
			devfreq_domain_name = "dvfs_aud";
			pm_qos_class = <22>; /* PM_QOS_AUD_THROUGHPUT */
			pm_qos_class_max = <27>; /* PM_QOS_AUD_THROUGHPUT_MAX */
			ess_flag = <ESS_FLAG_AUD>;
			dm-index = <DM_AUD>;

			/* Delay time */
			use_delay_time = "false";

			freq_info = <1180000 295000 295000 295000 1180000 295000>;
			/* <initial, default_qos, suspend_freq, min, max, reboot_freq> */

			/* Booting value */
			boot_info = <0 295000>;
			/* boot_qos_timeout, boot_freq */

			/* governor data */
			governor = <SIMPLE_INTERACTIVE>;

			bts_update = "false";
			dfs_id = <ACPM_DVFS_AUD>;

			power-domains = <&pd_aud>;
			pd_name = "pd-aud";
		};

		devfreq_6: devfreq_iva@17000070 {
			compatible = "samsung,exynos-devfreq";
			reg = <0x0 0x17000070 0x0>;
			devfreq_type = <DEVFREQ_IVA>;
			devfreq_domain_name = "dvfs_iva";
			pm_qos_class = <23>; /* PM_QOS_IVA_THROUGHPUT */
			pm_qos_class_max = <28>; /* PM_QOS_IVA_THROUGHPUT_MAX */
			ess_flag = <ESS_FLAG_IVA>;
			dm-index = <DM_IVA>;

			/* Delay time */
			use_delay_time = "false";

			freq_info = <56000 56000 56000 56000 534000 56000>;
			/* <initial, default_qos, suspend_freq, min, max, reboot_freq> */

			/* Booting value */
			boot_info = <40 56000>;
			/* boot_qos_timeout, boot_freq */

			/* governor data */
			governor = <SIMPLE_INTERACTIVE>;

			bts_update = "false";
			dfs_id = <ACPM_DVFS_IVA>;
		};

		devfreq_7: devfreq_score@17000080 {
			compatible = "samsung,exynos-devfreq";
			reg = <0x0 0x17000080 0x0>;
			devfreq_type = <DEVFREQ_SCORE>;
			devfreq_domain_name = "dvfs_score";
			pm_qos_class = <24>; /* PM_QOS_SCORE_THROUGHPUT */
			pm_qos_class_max = <29>; /* PM_QOS_SOCRE_THROUGHPUT_MAX */
			ess_flag = <ESS_FLAG_SCORE>;
			dm-index = <DM_SCORE>;

			/* Delay time */
			use_delay_time = "false";

			freq_info = <25000 25000 25000 25000 666000 25000>;
			/* <initial, default_qos, suspend_freq, min, max, reboot_freq> */

			/* Booting value */
			boot_info = <40 25000>;
			/* boot_qos_timeout, boot_freq */

			/* governor data */
			governor = <SIMPLE_INTERACTIVE>;

			bts_update = "false";
			dfs_id = <ACPM_DVFS_SCORE>;
		};

		devfreq_8: devfreq_mfc@17000090 {
			compatible = "samsung,exynos-devfreq";
			reg = <0x0 0x17000090 0x0>;
			devfreq_type = <DEVFREQ_MFC>;
			devfreq_domain_name = "dvfs_mfc";
			pm_qos_class = <31>; /* PM_QOS_MFC_THROUGHPUT */
			pm_qos_class_max = <33>; /* PM_QOS_MFC_THROUGHPUT_MAX */
			ess_flag = <ESS_FLAG_MFC>;
			dm-index = <DM_MFC>;

			/* Delay time */
			use_delay_time = "false";

			freq_info = <134000 134000 134000 134000 800000 134000>;
			/* <initial, default_qos, suspend_freq, min, max, reboot_freq> */

			/* Booting value */
			boot_info = <40 134000>;
			/* boot_qos_timeout, boot_freq */

			/* governor data */
			governor = <SIMPLE_INTERACTIVE>;

			bts_update = "false";
			dfs_id = <ACPM_DVFS_MFC>;
		};
		devfreq_9: devfreq_npu@170000A0 {
			compatible = "samsung,exynos-devfreq";
			reg = <0x0 0x170000A0 0x0>;
			devfreq_type = <DEVFREQ_NPU>;
			devfreq_domain_name = "dvfs_npu";
			pm_qos_class = <32>; /* PM_QOS_NPU_THROUGHPUT */
			pm_qos_class_max = <34>; /* PM_QOS_NPU_THROUGHPUT_MAX */
			ess_flag = <ESS_FLAG_NPU>;
			dm-index = <DM_NPU>;

			/* Delay time */
			use_delay_time = "false";

			freq_info = <167000 167000 167000 167000 933000 167000>;
			/* <initial, default_qos, suspend_freq, min, max, reboot_freq> */

			/* Booting value */
			boot_info = <0 167000>;
			/* boot_qos_timeout, boot_freq */

			/* governor data */
			governor = <SIMPLE_INTERACTIVE>;

			bts_update = "false";
			dfs_id = <ACPM_DVFS_NPU>;

			power-domains = <&pd_npu1>;
			pd_name = "pd-npu1";
		};
	};

	tmuctrl_0: BIG@10090000 {
		compatible = "samsung,exynos9820-tmu";
		reg = <0x0 0x10090000 0x800>;
		interrupts = <GIC_SPI INTREQ__TMU_TMU_TOP IRQ_TYPE_LEVEL_HIGH>;
		tmu_name = "BIG";
		id = <0>;
		sensors = <1984>;	/* 0x7C0 */
		sensing_mode = "balance";
		hotplug_enable = <1>;
		hotplug_in_threshold = <91>;
		hotplug_out_threshold = <96>;
		#include "exynos9810-tmu-sensor-conf.dtsi"
	};

	tmuctrl_1: MID@10090000 {
		compatible = "samsung,exynos9820-tmu";
		reg = <0x0 0x10090000 0x800>;
		interrupts = <GIC_SPI INTREQ__TMU_TMU_TOP IRQ_TYPE_LEVEL_HIGH>;
		tmu_name = "MID";
		id = <1>;
		sensors = <32>;		/* 0x20 */
		sensing_mode = "max";
		#include "exynos9810-tmu-sensor-conf.dtsi"
	};

	tmuctrl_2: LITTLE@10090000 {
		compatible = "samsung,exynos9820-tmu";
		reg = <0x0 0x10090000 0x800>;
		interrupts = <GIC_SPI INTREQ__TMU_TMU_TOP IRQ_TYPE_LEVEL_HIGH>;
		tmu_name = "LITTLE";
		id = <2>;
		sensors = <16>;		/* 0x10 */
		sensing_mode = "max";
		#include "exynos9810-tmu-sensor-conf.dtsi"
	};

	tmuctrl_3: G3D@100A0000 {
		compatible = "samsung,exynos9810-tmu";
		reg = <0x0 0x100A0000 0x800>;
		interrupts = <GIC_SPI INTREQ__TMU_TMU_SUB IRQ_TYPE_LEVEL_HIGH>;
		tmu_name = "G3D";
		id = <3>;
		sensors = <542>;	/* 0x21E */
		sensing_mode = "balance";
		#include "exynos9810-tmu-sensor-conf.dtsi"
	};

	tmuctrl_4: ISP@100A0000 {
		compatible = "samsung,exynos9810-tmu";
		reg = <0x0 0x100A0000 0x800>;
		interrupts = <GIC_SPI INTREQ__TMU_TMU_SUB IRQ_TYPE_LEVEL_HIGH>;
		tmu_name = "ISP";
		id = <4>;
		sensors = <256>;	/* 0x100 */
		sensing_mode = "max";
		#include "exynos9810-tmu-sensor-conf.dtsi"
	};

	acpm_tmu {
		acpm-ipc-channel = <9>;
	};

	thermal-zones {
		big_thermal: BIG {
			zone_name  = "BIG_THERMAL";
			polling-delay-passive = <50>;
			polling-delay = <1000>;
			thermal-sensors = <&tmuctrl_0>;
			governor = "power_allocator";
			sustainable-power = <0>;
			k_po = <0>;
			k_pu = <0>;
			k_i = <0>;
			i_max = <0>;
			integral_cutoff = <0>;

			trips {
				big_cold: big-cold {
					temperature = <20000>;
					hysteresis = <5000>; /* millicelsius */
					type = "active";
				};
				big_switch_on: big-switch-on {
					temperature = <55000>; /* millicelsius */
					hysteresis = <2000>; /* millicelsius */
					type = "active";
				};
				big_control_temp: big-control-temp {
					temperature = <83000>; /* millicelsius */
					hysteresis = <5000>; /* millicelsius */
					type = "passive";
				};
				big_alert0: big-alert0 {
					temperature = <95000>; /* millicelsius */
					hysteresis = <5000>; /* millicelsius */
					type = "active";
				};
				big_alert1: big-alert1 {
					temperature = <100000>; /* millicelsius */
					hysteresis = <5000>; /* millicelsius */
					type = "active";
				};
				big_alert2: big-alert2 {
					temperature = <105000>; /* millicelsius */
					hysteresis = <5000>; /* millicelsius */
					type = "active";
				};
				big_alert3: big-alert3 {
					temperature = <110000>; /* millicelsius */
					hysteresis = <5000>; /* millicelsius */
					type = "active";
				};
				big_hot: big-hot {
					temperature = <115000>; /* millicelsius */
					hysteresis = <5000>; /* millicelsius */
					type = "hot";
				};
			};

			cooling-maps {
				map0 {
				     trip = <&big_control_temp>;
				     cooling-device = <&cpufreq_domain2 THERMAL_NO_LIMIT THERMAL_NO_LIMIT>;
			       };
			};

		};

		mid_thermal: MID {
			zone_name  = "MID_THERMAL";
			polling-delay-passive = <50>;
			polling-delay = <1000>;
			thermal-sensors = <&tmuctrl_1>;
			governor = "power_allocator";
			sustainable-power = <0>;
			k_po = <0>;
			k_pu = <0>;
			k_i = <0>;
			i_max = <0>;
			integral_cutoff = <0>;

			trips {
				mid_cold: mid-cold {
					temperature = <20000>;
					hysteresis = <5000>; /* millicelsius */
					type = "active";
				};
				mid_switch_on: mid-switch-on {
					temperature = <55000>; /* millicelsius */
					hysteresis = <2000>; /* millicelsius */
					type = "active";
				};
				mid_control_temp: mid-control-temp {
					temperature = <83000>; /* millicelsius */
					hysteresis = <5000>; /* millicelsius */
					type = "passive";
				};
				mid_alert0: mid-alert0 {
					temperature = <95000>; /* millicelsius */
					hysteresis = <5000>; /* millicelsius */
					type = "active";
				};
				mid_alert1: mid-alert1 {
					temperature = <100000>; /* millicelsius */
					hysteresis = <5000>; /* millicelsius */
					type = "active";
				};
				mid_alert2: mid-alert2 {
					temperature = <105000>; /* millicelsius */
					hysteresis = <5000>; /* millicelsius */
					type = "active";
				};
				mid_alert3: mid-alert3 {
					temperature = <110000>; /* millicelsius */
					hysteresis = <5000>; /* millicelsius */
					type = "active";
				};
				mid_hot: mid-hot {
					temperature = <115000>; /* millicelsius */
					hysteresis = <5000>; /* millicelsius */
					type = "hot";
				};
			};
			cooling-maps {
				map0 {
				     trip = <&mid_control_temp>;
				     cooling-device = <&cpufreq_domain1 THERMAL_NO_LIMIT THERMAL_NO_LIMIT>;
			       };
			};
		};

		little_thermal: LITTLE {
			zone_name  = "LITTLE_THERMAL";
			polling-delay-passive = <0>;
			polling-delay = <0>;
			thermal-sensors = <&tmuctrl_2>;

			trips {
				little_alert0: little-alert0 {
					temperature = <20000>; /* millicelsius */
					hysteresis = <5000>; /* millicelsius */
					type = "active";
				};
				little_alert1: little-alert1 {
					temperature = <76000>; /* millicelsius */
					hysteresis = <5000>; /* millicelsius */
					type = "active";
				};
				little_alert2: little-alert2 {
					temperature = <81000>; /* millicelsius */
					hysteresis = <5000>; /* millicelsius */
					type = "active";
				};
				little_alert3: little-alert3 {
					temperature = <86000>; /* millicelsius */
					hysteresis = <5000>; /* millicelsius */
					type = "active";
				};
				little_alert4: little-alert4 {
					temperature = <91000>; /* millicelsius */
					hysteresis = <5000>; /* millicelsius */
					type = "active";
				};
				little_alert5: little-alert5 {
					temperature = <96000>; /* millicelsius */
					hysteresis = <5000>; /* millicelsius */
					type = "active";
				};
				little_alert6: little-alert6 {
					temperature = <101000>; /* millicelsius */
					hysteresis = <5000>; /* millicelsius */
					type = "active";
				};
				little_hot: little-hot {
					temperature = <115000>; /* millicelsius */
					hysteresis = <5000>; /* millicelsius */
					type = "hot";
				};
			};
			cooling-maps {
				map0 {
				     trip = <&little_alert0>;
				     cooling-device = <&cpufreq_domain0 0 0>;
				};
				map1 {
				     trip = <&little_alert1>;
				     cooling-device = <&cpufreq_domain0 0 0>;
			       };
				map2 {
				     trip = <&little_alert2>;
				     cooling-device = <&cpufreq_domain0 0 0>;
				};
				map3 {
				     trip = <&little_alert3>;
				     cooling-device = <&cpufreq_domain0 0 0>;
				};
				map4 {
				     trip = <&little_alert4>;
				     cooling-device = <&cpufreq_domain0 0 0>;
				};
				map5 {
				     trip = <&little_alert5>;
				     cooling-device = <&cpufreq_domain0 0 0>;
			       };
				map6 {
				     trip = <&little_alert6>;
				     cooling-device = <&cpufreq_domain0 0 0>;
				};
				map7 {
				     trip = <&little_hot>;
				     cooling-device = <&cpufreq_domain0 0 0>;
				};
			};
		};

		gpu_thermal: G3D {
			zone_name  = "G3D_THERMAL";
			polling-delay-passive = <100>;
			polling-delay = <0>;
			thermal-sensors = <&tmuctrl_3>;
			governor = "power_allocator";
			sustainable-power = <0>;
			k_po = <0>;
			k_pu = <0>;
			k_i = <0>;
			i_max = <0>;
			integral_cutoff = <0>;

			trips {
				gpu_cold: gpu-cold {
					temperature = <20000>;
					hysteresis = <5000>; /* millicelsius */
					type = "active";
				};
				gpu_switch_on: gpu-switch-on {
					temperature = <78000>; /* millicelsius */
					hysteresis = <2000>; /* millicelsius */
					type = "active";
				};
				gpu_control_temp: gpu-control-temp {
					temperature = <88000>; /* millicelsius */
					hysteresis = <5000>; /* millicelsius */
					type = "passive";
				};
				gpu_alert0: gpu-alert0 {
					temperature = <105000>; /* millicelsius */
					hysteresis = <5000>; /* millicelsius */
					type = "active";
				};
				gpu_alert1: gpu-alert1 {
					temperature = <110000>; /* millicelsius */
					hysteresis = <5000>; /* millicelsius */
					type = "active";
				};
				gpu_alert2: gpu-alert2 {
					temperature = <115000>; /* millicelsius */
					hysteresis = <5000>; /* millicelsius */
					type = "active";
				};
				gpu_alert3: gpu-alert3 {
					temperature = <115000>; /* millicelsius */
					hysteresis = <5000>; /* millicelsius */
					type = "active";
				};
				gpu_hot: gpu-hot {
					temperature = <115000>; /* millicelsius */
					hysteresis = <5000>; /* millicelsius */
					type = "hot";
				};
			};
			cooling-maps {
				map0 {
				     trip = <&gpu_control_temp>;
				     cooling-device = <&mali THERMAL_NO_LIMIT THERMAL_NO_LIMIT>;
			       };
			};
		};

	};

	/* Secure RPMB */
	ufs-srpmb {
		compatible = "samsung,ufs-srpmb";
		interrupts = <GIC_SPI INTREQ__RPMB IRQ_TYPE_LEVEL_HIGH>;
	};

	exynos_adc: adc@15C40000 {
		compatible = "samsung,exynos-adc-v3";
		reg = <0x0 0x15C40000 0x100>;
		interrupts = <GIC_SPI INTREQ__ADC_CMGP2AP IRQ_TYPE_LEVEL_HIGH>;
		#io-channel-cells = <1>;
		io-channel-ranges;
		clocks = <&clock GATE_ADC_CMGP_S0>;
		clock-names = "gate_adcif";
	};

	sec_pwm: pwm@10510000 {
		compatible = "samsung,s3c6400-pwm";
		reg = <0x0 0x10510000 0x1000>;
		samsung,pwm-outputs = <0>, <1>, <2>, <3>, <4>;
		#pwm-cells = <3>;
		clocks = <&clock GATE_PWM>, <&clock OSCCLK>;
		clock-names = "pwm_pclk", "pwm_sclk";
		status = "ok";
	};

	rtc@15950000 {
		compatible = "samsung,exynos8-rtc";
		reg = <0x0 0x15950000 0x100>;
		interrupts = <GIC_SPI INTREQ__RTC_ALARM_INT IRQ_TYPE_LEVEL_HIGH>,
			     <GIC_SPI INTREQ__RTC_TIC_INT_0 IRQ_TYPE_LEVEL_HIGH>;
	};

	/* tbase */
	tee {
		compatible = "samsung,exynos-tee";
		interrupts = <GIC_SPI INTREQ__TBASE IRQ_TYPE_LEVEL_HIGH>;
	};
};
